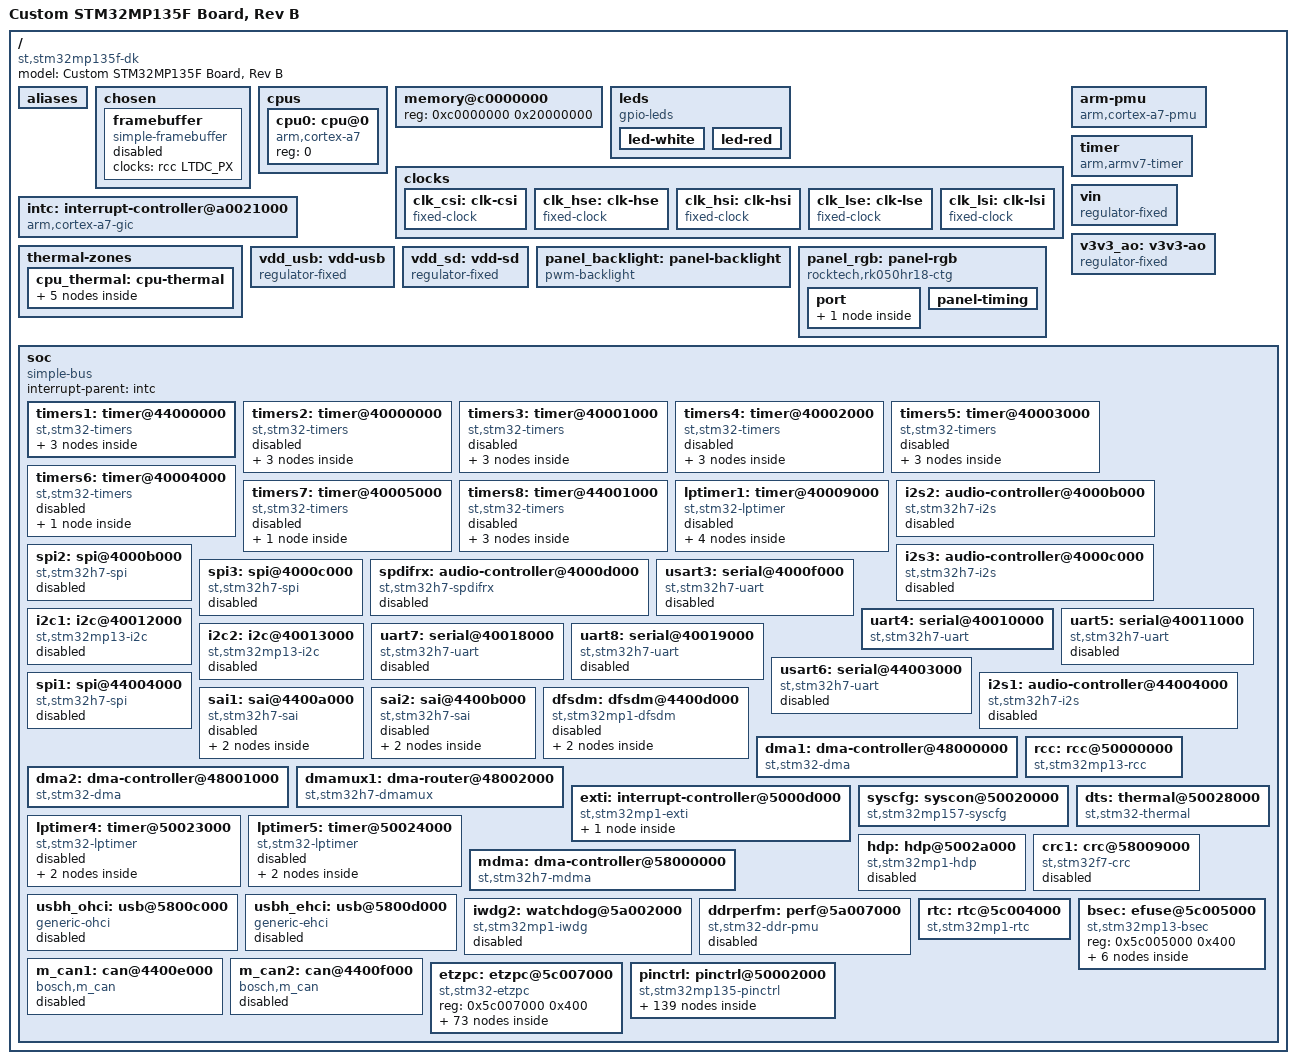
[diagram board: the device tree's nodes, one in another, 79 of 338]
// SPDX-License-Identifier: (GPL-2.0+ OR BSD-3-Clause)
/*
 * Copyright (C) STMicroelectronics 2021 - All Rights Reserved
 * Author: Alexandre Torgue <alexandre.torgue@foss.st.com> for STMicroelectronics.
 */

/dts-v1/;

#include <dt-bindings/gpio/gpio.h>
#include <dt-bindings/input/input.h>
#include <dt-bindings/leds/common.h>
#include <dt-bindings/rtc/rtc-stm32.h>
#include <dt-bindings/interrupt-controller/arm-gic.h>
#include <dt-bindings/clock/stm32mp13-clks.h>
#include <dt-bindings/regulator/st,stm32mp13-regulator.h>
#include <dt-bindings/reset/stm32mp13-resets.h>
#include <dt-bindings/thermal/thermal.h>
#include <dt-bindings/pinctrl/stm32-pinfunc.h>

#define STM32MP1_ETZPC_LPTIM2_ID	1
#define STM32MP1_ETZPC_LPTIM3_ID	2
#define STM32MP1_ETZPC_LTDC_ID		3
#define STM32MP1_ETZPC_DCMIPP_ID	4
#define STM32MP1_ETZPC_USBPHYCTRL_ID	5
#define STM32MP1_ETZPC_USART1_ID	16
#define STM32MP1_ETZPC_USART2_ID	17
#define STM32MP1_ETZPC_SPI4_ID		18
#define STM32MP1_ETZPC_SPI5_ID		19
#define STM32MP1_ETZPC_I2C3_ID		20
#define STM32MP1_ETZPC_I2C4_ID		21
#define STM32MP1_ETZPC_I2C5_ID		22
#define STM32MP1_ETZPC_TIM12_ID		23
#define STM32MP1_ETZPC_TIM13_ID		24
#define STM32MP1_ETZPC_TIM14_ID		25
#define STM32MP1_ETZPC_TIM15_ID		26
#define STM32MP1_ETZPC_TIM16_ID		27
#define STM32MP1_ETZPC_TIM17_ID		28
#define STM32MP1_ETZPC_ADC1_ID		32
#define STM32MP1_ETZPC_ADC2_ID		33
#define STM32MP1_ETZPC_OTG_ID		34
#define STM32MP1_ETZPC_RNG_ID		40
#define STM32MP1_ETZPC_HASH_ID		41
#define STM32MP1_ETZPC_ETH1_ID		48
#define STM32MP1_ETZPC_ETH2_ID		49
#define STM32MP1_ETZPC_SDMMC1_ID	50
#define STM32MP1_ETZPC_SDMMC2_ID	51
#define STM32MP1_ETZPC_FMC_ID		54
#define STM32MP1_ETZPC_QSPI_ID		55

/ {
	#address-cells = <1>;
	#size-cells = <1>;
	model = "Custom STM32MP135F Board, Rev B";
	compatible = "st,stm32mp135f-dk", "st,stm32mp135";

	aliases {
		ethernet0 = &eth1;
		ethernet1 = &eth2;
		mmc0 = &sdmmc1;
		mmc1 = &sdmmc2;
		serial0 = &uart4;
		serial1 = &usart1;
		serial2 = &uart8;
		serial3 = &usart2;
	};

	chosen {
		//bootargs = "ubi.mtd=rootfs root=ubi0:rootfs rootfstype=ubifs";
		bootargs = "root=/dev/mmcblk0p3 rootwait console=tty0 console=ttySTM0,115200";
		stdout-path = "serial0:115200n8";
		#address-cells = <1>;
		#size-cells = <1>;
		ranges;

		framebuffer {
			compatible = "simple-framebuffer";
			clocks = <&rcc LTDC_PX>;
			status = "disabled";
		};
	};

	cpus {
		#address-cells = <1>;
		#size-cells = <0>;

		cpu0: cpu@0 {
			compatible = "arm,cortex-a7";
			device_type = "cpu";
			reg = <0>;
			#cooling-cells = <2>;
		};
	};

	memory@c0000000 {
		device_type = "memory";
		reg = <0xc0000000 0x20000000>;
	};

	leds {
		compatible = "gpio-leds";

		led-white {
			function = LED_FUNCTION_HEARTBEAT;
			color = <LED_COLOR_ID_WHITE>;
			gpios = <&gpioa 4 GPIO_ACTIVE_HIGH>;
			linux,default-trigger = "heartbeat";
			default-state = "off";
		};

		led-red {
			function = LED_FUNCTION_ACTIVITY;
			color = <LED_COLOR_ID_RED>;
			gpios = <&gpioa 13 GPIO_ACTIVE_LOW>;
			linux,default-trigger = "timer";
			default-state = "off";
		};
	};

	clocks {
		clk_csi: clk-csi {
			#clock-cells = <0>;
			compatible = "fixed-clock";
			clock-frequency = <4000000>;
			clock-output-names = "ck_csi";
		};

		clk_hse: clk-hse {
			#clock-cells = <0>;
			compatible = "fixed-clock";
			clock-frequency = <24000000>;
			clock-output-names = "ck_hse";
		};

		clk_hsi: clk-hsi {
			#clock-cells = <0>;
			compatible = "fixed-clock";
			clock-frequency = <64000000>;
			clock-output-names = "ck_hsi";
		};

		clk_lse: clk-lse {
			#clock-cells = <0>;
			compatible = "fixed-clock";
			clock-frequency = <32768>;
			clock-output-names = "ck_lse";
		};

		clk_lsi: clk-lsi {
			#clock-cells = <0>;
			compatible = "fixed-clock";
			clock-frequency = <32000>;
			clock-output-names = "ck_lsi";
		};
	};

	intc: interrupt-controller@a0021000 {
		compatible = "arm,cortex-a7-gic";
		#interrupt-cells = <3>;
		interrupt-controller;
		reg = <0xa0021000 0x1000>,
		      <0xa0022000 0x2000>;
	};

	arm-pmu {
		compatible = "arm,cortex-a7-pmu";
		interrupts = <GIC_SPI 133 IRQ_TYPE_LEVEL_HIGH>;
		interrupt-affinity = <&cpu0>;
		interrupt-parent = <&intc>;
	};

	timer {
		compatible = "arm,armv7-timer";
		interrupts = <GIC_PPI 13 (GIC_CPU_MASK_SIMPLE(1) | IRQ_TYPE_LEVEL_LOW)>,
			     <GIC_PPI 14 (GIC_CPU_MASK_SIMPLE(1) | IRQ_TYPE_LEVEL_LOW)>,
			     <GIC_PPI 11 (GIC_CPU_MASK_SIMPLE(1) | IRQ_TYPE_LEVEL_LOW)>,
			     <GIC_PPI 10 (GIC_CPU_MASK_SIMPLE(1) | IRQ_TYPE_LEVEL_LOW)>;
		interrupt-parent = <&intc>;
		always-on;
	};

	thermal-zones {
		cpu_thermal: cpu-thermal {
			polling-delay-passive = <0>;
			polling-delay = <0>;
			thermal-sensors = <&dts>;

			trips {
				cpu_alert: cpu-alert0 {
					temperature = <95000>;
					hysteresis = <10000>;
					type = "passive";
				};
				cpu_crit: cpu-crit0 {
					temperature = <120000>;
					hysteresis = <0>;
					type = "critical";
				};
			};

			cooling-maps {
				map0 {
					trip = <&cpu_alert>;
					cooling-device = <&cpu0 1 1>;
				};
			};
		};
	};

	vin: vin {
		compatible = "regulator-fixed";
		regulator-name = "vin";
		regulator-min-microvolt = <5000000>;
		regulator-max-microvolt = <5000000>;
		regulator-always-on;
	};

	v3v3_ao: v3v3-ao {
		compatible = "regulator-fixed";
		regulator-name = "v3v3_ao";
		regulator-min-microvolt = <3300000>;
		regulator-max-microvolt = <3300000>;
		regulator-always-on;
	};

	vdd_usb: vdd-usb {
		compatible = "regulator-fixed";
		regulator-name = "vdd_usb";
		regulator-min-microvolt = <3300000>;
		regulator-max-microvolt = <3300000>;
		regulator-always-on;
	};

	vdd_sd: vdd-sd {
		compatible = "regulator-fixed";
		regulator-name = "vdd_sd";
		regulator-min-microvolt = <3300000>;
		regulator-max-microvolt = <3300000>;
		regulator-always-on;
	};

	panel_backlight: panel-backlight {
		compatible = "pwm-backlight";
		pwms = <&pwm1 2 1000000 0>;
		brightness-levels = <0 16 32 64 128 255>;
		default-brightness-level = <4>;
		power-supply = <&v3v3_ao>;
		default-on;
		status = "okay";
	};

	panel_rgb: panel-rgb {
		compatible = "rocktech,rk050hr18-ctg", "panel-dpi";
		enable-gpios = <&gpiog 7 GPIO_ACTIVE_HIGH>;
		backlight = <&panel_backlight>;
		power-supply = <&v3v3_ao>;
		data-mapping = "rgb565";
		status = "okay";

		width-mm = <108>;
		height-mm = <65>;

		port {
			panel_in_rgb: endpoint {
				remote-endpoint = <&ltdc_out_rgb>;
			};
		};

		panel-timing {
			clock-frequency = <24000000>;
			hactive = <800>;
			vactive = <480>;
			hsync-len = <4>;
			hfront-porch = <8>;
			hback-porch = <8>;
			vsync-len = <4>;
			vfront-porch = <16>;
			vback-porch = <16>;
			hsync-active = <0>;
			vsync-active = <0>;
			de-active = <1>;
			pixelclk-active = <1>;
		};
	};

	soc {
		compatible = "simple-bus";
		#address-cells = <1>;
		#size-cells = <1>;
		interrupt-parent = <&intc>;
		ranges;

		timers1: timer@44000000 {
			#address-cells = <1>;
			#size-cells = <0>;
			compatible = "st,stm32-timers";
			reg = <0x44000000 0x400>;
			interrupts = <GIC_SPI 25 IRQ_TYPE_LEVEL_HIGH>,
				     <GIC_SPI 26 IRQ_TYPE_LEVEL_HIGH>,
				     <GIC_SPI 27 IRQ_TYPE_LEVEL_HIGH>,
				     <GIC_SPI 28 IRQ_TYPE_LEVEL_HIGH>;
			interrupt-names = "brk", "up", "trg-com", "cc";
			clocks = <&rcc TIM1_K>;
			clock-names = "int";
			//dmas = <&dmamux1 11 0x400 0x1>,
			//       <&dmamux1 12 0x400 0x1>,
			//       <&dmamux1 13 0x400 0x1>,
			//       <&dmamux1 14 0x400 0x1>,
			//       <&dmamux1 15 0x400 0x1>,
			//       <&dmamux1 16 0x400 0x1>,
			//       <&dmamux1 17 0x400 0x1>;
			//dma-names = "ch1", "ch2", "ch3", "ch4",
			//	    "up", "trig", "com";
			status = "okay";

			pwm1: pwm {
				compatible = "st,stm32-pwm";
				#pwm-cells = <3>;
				status = "okay";
				pinctrl-0 = <&pwm1_pins>;
				pinctrl-names = "default";
			};

			timer@0 {
				compatible = "st,stm32h7-timer-trigger";
				reg = <0>;
				status = "disabled";
			};

			counter {
				compatible = "st,stm32-timer-counter";
				status = "disabled";
			};
		};

		timers2: timer@40000000 {
			#address-cells = <1>;
			#size-cells = <0>;
			compatible = "st,stm32-timers";
			reg = <0x40000000 0x400>;
			interrupts = <GIC_SPI 29 IRQ_TYPE_LEVEL_HIGH>;
			interrupt-names = "global";
			clocks = <&rcc TIM2_K>;
			clock-names = "int";
			dmas = <&dmamux1 18 0x400 0x1>,
			       <&dmamux1 19 0x400 0x1>,
			       <&dmamux1 20 0x400 0x1>,
			       <&dmamux1 21 0x400 0x1>,
			       <&dmamux1 22 0x400 0x1>;
			dma-names = "ch1", "ch2", "ch3", "ch4", "up";
			status = "disabled";

			pwm {
				compatible = "st,stm32-pwm";
				#pwm-cells = <3>;
				status = "disabled";
			};

			timer@1 {
				compatible = "st,stm32h7-timer-trigger";
				reg = <1>;
				status = "disabled";
			};

			counter {
				compatible = "st,stm32-timer-counter";
				status = "disabled";
			};
		};

		timers3: timer@40001000 {
			#address-cells = <1>;
			#size-cells = <0>;
			compatible = "st,stm32-timers";
			reg = <0x40001000 0x400>;
			interrupts = <GIC_SPI 30 IRQ_TYPE_LEVEL_HIGH>;
			interrupt-names = "global";
			clocks = <&rcc TIM3_K>;
			clock-names = "int";
			dmas = <&dmamux1 23 0x400 0x1>,
			       <&dmamux1 24 0x400 0x1>,
			       <&dmamux1 25 0x400 0x1>,
			       <&dmamux1 26 0x400 0x1>,
			       <&dmamux1 27 0x400 0x1>,
			       <&dmamux1 28 0x400 0x1>;
			dma-names = "ch1", "ch2", "ch3", "ch4", "up", "trig";
			status = "disabled";

			pwm {
				compatible = "st,stm32-pwm";
				#pwm-cells = <3>;
				status = "disabled";
			};

			timer@2 {
				compatible = "st,stm32h7-timer-trigger";
				reg = <2>;
				status = "disabled";
			};

			counter {
				compatible = "st,stm32-timer-counter";
				status = "disabled";
			};
		};

		timers4: timer@40002000 {
			#address-cells = <1>;
			#size-cells = <0>;
			compatible = "st,stm32-timers";
			reg = <0x40002000 0x400>;
			interrupts = <GIC_SPI 31 IRQ_TYPE_LEVEL_HIGH>;
			interrupt-names = "global";
			clocks = <&rcc TIM4_K>;
			clock-names = "int";
			dmas = <&dmamux1 29 0x400 0x1>,
			       <&dmamux1 30 0x400 0x1>,
			       <&dmamux1 31 0x400 0x1>,
			       <&dmamux1 32 0x400 0x1>;
			dma-names = "ch1", "ch2", "ch3", "up";
			status = "disabled";

			pwm {
				compatible = "st,stm32-pwm";
				#pwm-cells = <3>;
				status = "disabled";
			};

			timer@3 {
				compatible = "st,stm32h7-timer-trigger";
				reg = <3>;
				status = "disabled";
			};

			counter {
				compatible = "st,stm32-timer-counter";
				status = "disabled";
			};
		};

		timers5: timer@40003000 {
			#address-cells = <1>;
			#size-cells = <0>;
			compatible = "st,stm32-timers";
			reg = <0x40003000 0x400>;
			interrupts = <GIC_SPI 51 IRQ_TYPE_LEVEL_HIGH>;
			interrupt-names = "global";
			clocks = <&rcc TIM5_K>;
			clock-names = "int";
			dmas = <&dmamux1 55 0x400 0x1>,
			       <&dmamux1 56 0x400 0x1>,
			       <&dmamux1 57 0x400 0x1>,
			       <&dmamux1 58 0x400 0x1>,
			       <&dmamux1 59 0x400 0x1>,
			       <&dmamux1 60 0x400 0x1>;
			dma-names = "ch1", "ch2", "ch3", "ch4", "up", "trig";
			status = "disabled";

			pwm {
				compatible = "st,stm32-pwm";
				#pwm-cells = <3>;
				status = "disabled";
			};

			timer@4 {
				compatible = "st,stm32h7-timer-trigger";
				reg = <4>;
				status = "disabled";
			};

			counter {
				compatible = "st,stm32-timer-counter";
				status = "disabled";
			};
		};

		timers6: timer@40004000 {
			#address-cells = <1>;
			#size-cells = <0>;
			compatible = "st,stm32-timers";
			reg = <0x40004000 0x400>;
			interrupts = <GIC_SPI 55 IRQ_TYPE_LEVEL_HIGH>;
			interrupt-names = "global";
			clocks = <&rcc TIM6_K>;
			clock-names = "int";
			dmas = <&dmamux1 69 0x400 0x1>;
			dma-names = "up";
			status = "disabled";

			timer@5 {
				compatible = "st,stm32h7-timer-trigger";
				reg = <5>;
				status = "disabled";
			};
		};

		timers7: timer@40005000 {
			#address-cells = <1>;
			#size-cells = <0>;
			compatible = "st,stm32-timers";
			reg = <0x40005000 0x400>;
			interrupts = <GIC_SPI 56 IRQ_TYPE_LEVEL_HIGH>;
			interrupt-names = "global";
			clocks = <&rcc TIM7_K>;
			clock-names = "int";
			dmas = <&dmamux1 70 0x400 0x1>;
			dma-names = "up";
			status = "disabled";

			timer@6 {
				compatible = "st,stm32h7-timer-trigger";
				reg = <6>;
				status = "disabled";
			};
		};

		timers8: timer@44001000 {
			#address-cells = <1>;
			#size-cells = <0>;
			compatible = "st,stm32-timers";
			reg = <0x44001000 0x400>;
			interrupts = <GIC_SPI 44 IRQ_TYPE_LEVEL_HIGH>,
				     <GIC_SPI 45 IRQ_TYPE_LEVEL_HIGH>,
				     <GIC_SPI 46 IRQ_TYPE_LEVEL_HIGH>,
				     <GIC_SPI 47 IRQ_TYPE_LEVEL_HIGH>;
			interrupt-names = "brk", "up", "trg-com", "cc";
			clocks = <&rcc TIM8_K>;
			clock-names = "int";
			dmas = <&dmamux1 47 0x400 0x1>,
			       <&dmamux1 48 0x400 0x1>,
			       <&dmamux1 49 0x400 0x1>,
			       <&dmamux1 50 0x400 0x1>,
			       <&dmamux1 51 0x400 0x1>,
			       <&dmamux1 52 0x400 0x1>,
			       <&dmamux1 53 0x400 0x1>;
			dma-names = "ch1", "ch2", "ch3", "ch4",
				    "up", "trig", "com";
			status = "disabled";

			pwm {
				compatible = "st,stm32-pwm";
				#pwm-cells = <3>;
				status = "disabled";
			};

			timer@7 {
				compatible = "st,stm32h7-timer-trigger";
				reg = <7>;
				status = "disabled";
			};

			counter {
				compatible = "st,stm32-timer-counter";
				status = "disabled";
			};
		};

		lptimer1: timer@40009000 {
			#address-cells = <1>;
			#size-cells = <0>;
			compatible = "st,stm32-lptimer";
			reg = <0x40009000 0x400>;
			interrupts-extended = <&exti 47 IRQ_TYPE_LEVEL_HIGH>;
			clocks = <&rcc LPTIM1_K>;
			clock-names = "mux";
			//power-domains = <&pd_core_ret>;
			wakeup-source;
			status = "disabled";

			pwm {
				compatible = "st,stm32-pwm-lp";
				#pwm-cells = <3>;
				status = "disabled";
			};

			trigger@0 {
				compatible = "st,stm32-lptimer-trigger";
				reg = <0>;
				status = "disabled";
			};

			counter {
				compatible = "st,stm32-lptimer-counter";
				status = "disabled";
			};

			timer {
				compatible = "st,stm32-lptimer-timer";
				status = "disabled";
			};
		};

		i2s2: audio-controller@4000b000 {
			compatible = "st,stm32h7-i2s";
			#sound-dai-cells = <0>;
			reg = <0x4000b000 0x400>;
			interrupts = <GIC_SPI 37 IRQ_TYPE_LEVEL_HIGH>;
			dmas = <&dmamux1 39 0x400 0x01>,
			       <&dmamux1 40 0x400 0x01>;
			dma-names = "rx", "tx";
			status = "disabled";
		};

		spi2: spi@4000b000 {
			compatible = "st,stm32h7-spi";
			reg = <0x4000b000 0x400>;
			interrupts = <GIC_SPI 37 IRQ_TYPE_LEVEL_HIGH>;
			clocks = <&rcc SPI2_K>;
			resets = <&rcc SPI2_R>;
			#address-cells = <1>;
			#size-cells = <0>;
			dmas = <&dmamux1 39 0x400 0x01>,
			       <&dmamux1 40 0x400 0x01>;
			dma-names = "rx", "tx";
			status = "disabled";
		};

		i2s3: audio-controller@4000c000 {
			compatible = "st,stm32h7-i2s";
			#sound-dai-cells = <0>;
			reg = <0x4000c000 0x400>;
			interrupts = <GIC_SPI 52 IRQ_TYPE_LEVEL_HIGH>;
			dmas = <&dmamux1 61 0x400 0x01>,
			       <&dmamux1 62 0x400 0x01>;
			dma-names = "rx", "tx";
			status = "disabled";
		};

		spi3: spi@4000c000 {
			compatible = "st,stm32h7-spi";
			reg = <0x4000c000 0x400>;
			interrupts = <GIC_SPI 52 IRQ_TYPE_LEVEL_HIGH>;
			clocks = <&rcc SPI3_K>;
			resets = <&rcc SPI3_R>;
			#address-cells = <1>;
			#size-cells = <0>;
			dmas = <&dmamux1 61 0x400 0x01>,
			       <&dmamux1 62 0x400 0x01>;
			dma-names = "rx", "tx";
			status = "disabled";
		};

		spdifrx: audio-controller@4000d000 {
			compatible = "st,stm32h7-spdifrx";
			#sound-dai-cells = <0>;
			reg = <0x4000d000 0x400>;
			clocks = <&rcc SPDIF_K>;
			clock-names = "kclk";
			interrupts = <GIC_SPI 95 IRQ_TYPE_LEVEL_HIGH>;
			dmas = <&dmamux1 93 0x400 0x01>,
			       <&dmamux1 94 0x400 0x01>;
			dma-names = "rx", "rx-ctrl";
			status = "disabled";
		};

		usart3: serial@4000f000 {
			compatible = "st,stm32h7-uart";
			reg = <0x4000f000 0x400>;
			interrupts-extended = <&exti 28 IRQ_TYPE_LEVEL_HIGH>;
			clocks = <&rcc USART3_K>;
			resets = <&rcc USART3_R>;
			wakeup-source;
			//power-domains = <&pd_core_ret>;
			dmas = <&dmamux1 45 0x400 0x5>,
			       <&dmamux1 46 0x400 0x1>;
			dma-names = "rx", "tx";
			status = "disabled";
		};

		uart4: serial@40010000 {
			compatible = "st,stm32h7-uart";
			reg = <0x40010000 0x400>;
			interrupts = <GIC_SPI 53 IRQ_TYPE_LEVEL_HIGH>;
			clocks = <&rcc UART4_K>;
			resets = <&rcc UART4_R>;
			wakeup-source;
			//power-domains = <&pd_core_ret>;
			pinctrl-names = "default", "sleep", "idle";
			pinctrl-0 = <&uart4_pins_a>;
			pinctrl-1 = <&uart4_sleep_pins_a>;
			pinctrl-2 = <&uart4_idle_pins_a>;
			status = "okay";
		};

		uart5: serial@40011000 {
			compatible = "st,stm32h7-uart";
			reg = <0x40011000 0x400>;
			interrupts-extended = <&exti 31 IRQ_TYPE_LEVEL_HIGH>;
			clocks = <&rcc UART5_K>;
			resets = <&rcc UART5_R>;
			wakeup-source;
			//power-domains = <&pd_core_ret>;
			dmas = <&dmamux1 65 0x400 0x5>,
			       <&dmamux1 66 0x400 0x1>;
			dma-names = "rx", "tx";
			status = "disabled";
		};

		i2c1: i2c@40012000 {
			compatible = "st,stm32mp13-i2c";
			reg = <0x40012000 0x400>;
			interrupt-names = "event", "error";
			interrupts = <GIC_SPI 32 IRQ_TYPE_LEVEL_HIGH>,
				     <GIC_SPI 33 IRQ_TYPE_LEVEL_HIGH>;
			clocks = <&rcc I2C1_K>;
			resets = <&rcc I2C1_R>;
			#address-cells = <1>;
			#size-cells = <0>;
			dmas = <&dmamux1 33 0x400 0x1>,
			       <&dmamux1 34 0x400 0x1>;
			dma-names = "rx", "tx";
			st,syscfg-fmp = <&syscfg 0x4 0x1>;
			i2c-analog-filter;
			status = "disabled";
		};

		i2c2: i2c@40013000 {
			compatible = "st,stm32mp13-i2c";
			reg = <0x40013000 0x400>;
			interrupt-names = "event", "error";
			interrupts = <GIC_SPI 34 IRQ_TYPE_LEVEL_HIGH>,
				     <GIC_SPI 35 IRQ_TYPE_LEVEL_HIGH>;
			clocks = <&rcc I2C2_K>;
			resets = <&rcc I2C2_R>;
			#address-cells = <1>;
			#size-cells = <0>;
			dmas = <&dmamux1 35 0x400 0x1>,
			       <&dmamux1 36 0x400 0x1>;
			dma-names = "rx", "tx";
			st,syscfg-fmp = <&syscfg 0x4 0x2>;
			i2c-analog-filter;
			status = "disabled";
		};

		uart7: serial@40018000 {
			compatible = "st,stm32h7-uart";
			reg = <0x40018000 0x400>;
			interrupts-extended = <&exti 32 IRQ_TYPE_LEVEL_HIGH>;
			clocks = <&rcc UART7_K>;
			resets = <&rcc UART7_R>;
			wakeup-source;
			//power-domains = <&pd_core_ret>;
			dmas = <&dmamux1 79 0x400 0x5>,
			       <&dmamux1 80 0x400 0x1>;
			dma-names = "rx", "tx";
			status = "disabled";
		};

		uart8: serial@40019000 {
			compatible = "st,stm32h7-uart";
			reg = <0x40019000 0x400>;
			interrupts-extended = <&exti 33 IRQ_TYPE_LEVEL_HIGH>;
			clocks = <&rcc UART8_K>;
			resets = <&rcc UART8_R>;
			wakeup-source;
			//power-domains = <&pd_core_ret>;
			dmas = <&dmamux1 81 0x400 0x5>,
			       <&dmamux1 82 0x400 0x1>;
			dma-names = "rx", "tx";
			status = "disabled";
		};

		usart6: serial@44003000 {
			compatible = "st,stm32h7-uart";
			reg = <0x44003000 0x400>;
			interrupts-extended = <&exti 29 IRQ_TYPE_LEVEL_HIGH>;
			clocks = <&rcc USART6_K>;
			resets = <&rcc USART6_R>;
			wakeup-source;
			//power-domains = <&pd_core_ret>;
			dmas = <&dmamux1 71 0x400 0x5>,
			       <&dmamux1 72 0x400 0x1>;
			dma-names = "rx", "tx";
			status = "disabled";
		};

		i2s1: audio-controller@44004000 {
			compatible = "st,stm32h7-i2s";
			#sound-dai-cells = <0>;
			reg = <0x44004000 0x400>;
			interrupts = <GIC_SPI 36 IRQ_TYPE_LEVEL_HIGH>;
			dmas = <&dmamux1 37 0x400 0x01>,
			       <&dmamux1 38 0x400 0x01>;
			dma-names = "rx", "tx";
			status = "disabled";
		};

		spi1: spi@44004000 {
			compatible = "st,stm32h7-spi";
			reg = <0x44004000 0x400>;
			interrupts = <GIC_SPI 36 IRQ_TYPE_LEVEL_HIGH>;
			clocks = <&rcc SPI1_K>;
			resets = <&rcc SPI1_R>;
			#address-cells = <1>;
			#size-cells = <0>;
			dmas = <&dmamux1 37 0x400 0x01>,
			       <&dmamux1 38 0x400 0x01>;
			dma-names = "rx", "tx";
			status = "disabled";
		};

		sai1: sai@4400a000 {
			compatible = "st,stm32h7-sai";
			#address-cells = <1>;
			#size-cells = <1>;
			ranges = <0 0x4400a000 0x400>;
			reg = <0x4400a000 0x4>, <0x4400a3f0 0x10>;
			interrupts = <GIC_SPI 87 IRQ_TYPE_LEVEL_HIGH>;
			resets = <&rcc SAI1_R>;
			status = "disabled";

			sai1a: audio-controller@4400a004 {
				#sound-dai-cells = <0>;

				compatible = "st,stm32-sai-sub-a";
				reg = <0x4 0x20>;
				clocks = <&rcc SAI1_K>;
				clock-names = "sai_ck";
				dmas = <&dmamux1 87 0x400 0x01>;
				status = "disabled";
			};

			sai1b: audio-controller@4400a024 {
				#sound-dai-cells = <0>;
				compatible = "st,stm32-sai-sub-b";
				reg = <0x24 0x20>;
				clocks = <&rcc SAI1_K>;
				clock-names = "sai_ck";
				dmas = <&dmamux1 88 0x400 0x01>;
				status = "disabled";
			};
		};

		sai2: sai@4400b000 {
			compatible = "st,stm32h7-sai";
			#address-cells = <1>;
			#size-cells = <1>;
			ranges = <0 0x4400b000 0x400>;
			reg = <0x4400b000 0x4>, <0x4400b3f0 0x10>;
			interrupts = <GIC_SPI 90 IRQ_TYPE_LEVEL_HIGH>;
			resets = <&rcc SAI2_R>;
			status = "disabled";

			sai2a: audio-controller@4400b004 {
				#sound-dai-cells = <0>;
				compatible = "st,stm32-sai-sub-a";
				reg = <0x4 0x20>;
				clocks = <&rcc SAI2_K>;
				clock-names = "sai_ck";
				dmas = <&dmamux1 89 0x400 0x01>;
				status = "disabled";
			};

			sai2b: audio-controller@4400b024 {
				#sound-dai-cells = <0>;
				compatible = "st,stm32-sai-sub-b";
				reg = <0x24 0x20>;
				clocks = <&rcc SAI2_K>;
				clock-names = "sai_ck";
				dmas = <&dmamux1 90 0x400 0x01>;
				status = "disabled";
			};
		};

		dfsdm: dfsdm@4400d000 {
			compatible = "st,stm32mp1-dfsdm";
			reg = <0x4400d000 0x800>;
			clocks = <&rcc DFSDM_K>;
			clock-names = "dfsdm";
			#address-cells = <1>;
			#size-cells = <0>;
			status = "disabled";

			dfsdm0: filter@0 {
				compatible = "st,stm32-dfsdm-adc";
				#io-channel-cells = <1>;
				reg = <0>;
				interrupts = <GIC_SPI 140 IRQ_TYPE_LEVEL_HIGH>;
				dmas = <&dmamux1 101 0x400 0x01>;
				dma-names = "rx";
				status = "disabled";
			};

			dfsdm1: filter@1 {
				compatible = "st,stm32-dfsdm-adc";
				#io-channel-cells = <1>;
				reg = <1>;
				interrupts = <GIC_SPI 141 IRQ_TYPE_LEVEL_HIGH>;
				dmas = <&dmamux1 102 0x400 0x01>;
				dma-names = "rx";
				status = "disabled";
			};
		};

		dma1: dma-controller@48000000 {
			compatible = "st,stm32-dma";
			reg = <0x48000000 0x400>;
			interrupts = <GIC_SPI 11 IRQ_TYPE_LEVEL_HIGH>,
				     <GIC_SPI 12 IRQ_TYPE_LEVEL_HIGH>,
				     <GIC_SPI 13 IRQ_TYPE_LEVEL_HIGH>,
				     <GIC_SPI 14 IRQ_TYPE_LEVEL_HIGH>,
				     <GIC_SPI 15 IRQ_TYPE_LEVEL_HIGH>,
				     <GIC_SPI 16 IRQ_TYPE_LEVEL_HIGH>,
				     <GIC_SPI 17 IRQ_TYPE_LEVEL_HIGH>,
				     <GIC_SPI 48 IRQ_TYPE_LEVEL_HIGH>;
			clocks = <&rcc DMA1>;
			resets = <&rcc DMA1_R>;
			#dma-cells = <4>;
			st,mem2mem;
			dma-requests = <8>;
		};

		dma2: dma-controller@48001000 {
			compatible = "st,stm32-dma";
			reg = <0x48001000 0x400>;
			interrupts = <GIC_SPI 57 IRQ_TYPE_LEVEL_HIGH>,
				     <GIC_SPI 58 IRQ_TYPE_LEVEL_HIGH>,
				     <GIC_SPI 59 IRQ_TYPE_LEVEL_HIGH>,
				     <GIC_SPI 60 IRQ_TYPE_LEVEL_HIGH>,
				     <GIC_SPI 61 IRQ_TYPE_LEVEL_HIGH>,
				     <GIC_SPI 69 IRQ_TYPE_LEVEL_HIGH>,
				     <GIC_SPI 70 IRQ_TYPE_LEVEL_HIGH>,
				     <GIC_SPI 71 IRQ_TYPE_LEVEL_HIGH>;
			clocks = <&rcc DMA2>;
			resets = <&rcc DMA2_R>;
			#dma-cells = <4>;
			st,mem2mem;
			dma-requests = <8>;
		};

		dmamux1: dma-router@48002000 {
			compatible = "st,stm32h7-dmamux";
			reg = <0x48002000 0x40>;
			clocks = <&rcc DMAMUX1>;
			resets = <&rcc DMAMUX1_R>;
			#dma-cells = <3>;
			dma-masters = <&dma1 &dma2>;
			dma-requests = <128>;
			dma-channels = <16>;
		};

		rcc: rcc@50000000 {
			compatible = "st,stm32mp13-rcc", "syscon";
			reg = <0x50000000 0x1000>;
			#clock-cells = <1>;
			#reset-cells = <1>;
			clock-names = "hse", "hsi", "csi", "ck_lse", "lsi";
			clocks = <&clk_hse>,
				 <&clk_hsi>,
				 <&clk_csi>,
				 <&clk_lse>,
				 <&clk_lsi>;
		};

		exti: interrupt-controller@5000d000 {
			compatible = "st,stm32mp1-exti", "syscon";
			interrupt-controller;
			#interrupt-cells = <2>;
			#address-cells = <0>;
			reg = <0x5000d000 0x400>;

			exti-interrupt-map {
				#address-cells = <0>;
				#interrupt-cells = <2>;
				interrupt-map-mask = <0xffffffff 0>;
				interrupt-map =
					<0  0 &intc GIC_SPI 6   IRQ_TYPE_LEVEL_HIGH>,
					<1  0 &intc GIC_SPI 7   IRQ_TYPE_LEVEL_HIGH>,
					<2  0 &intc GIC_SPI 8   IRQ_TYPE_LEVEL_HIGH>,
					<3  0 &intc GIC_SPI 9   IRQ_TYPE_LEVEL_HIGH>,
					<4  0 &intc GIC_SPI 10  IRQ_TYPE_LEVEL_HIGH>,
					<5  0 &intc GIC_SPI 24  IRQ_TYPE_LEVEL_HIGH>,
					<6  0 &intc GIC_SPI 65  IRQ_TYPE_LEVEL_HIGH>,
					<7  0 &intc GIC_SPI 66  IRQ_TYPE_LEVEL_HIGH>,
					<8  0 &intc GIC_SPI 67  IRQ_TYPE_LEVEL_HIGH>,
					<9  0 &intc GIC_SPI 68  IRQ_TYPE_LEVEL_HIGH>,
					<10 0 &intc GIC_SPI 41  IRQ_TYPE_LEVEL_HIGH>,
					<11 0 &intc GIC_SPI 43  IRQ_TYPE_LEVEL_HIGH>,
					<12 0 &intc GIC_SPI 77  IRQ_TYPE_LEVEL_HIGH>,
					<13 0 &intc GIC_SPI 78  IRQ_TYPE_LEVEL_HIGH>,
					<14 0 &intc GIC_SPI 106 IRQ_TYPE_LEVEL_HIGH>,
					<15 0 &intc GIC_SPI 109 IRQ_TYPE_LEVEL_HIGH>,
					<16 0 &intc GIC_SPI 1   IRQ_TYPE_LEVEL_HIGH>,
					<19 0 &intc GIC_SPI 3   IRQ_TYPE_LEVEL_HIGH>,
					<21 0 &intc GIC_SPI 32  IRQ_TYPE_LEVEL_HIGH>,
					<22 0 &intc GIC_SPI 34  IRQ_TYPE_LEVEL_HIGH>,
					<23 0 &intc GIC_SPI 73  IRQ_TYPE_LEVEL_HIGH>,
					<24 0 &intc GIC_SPI 93  IRQ_TYPE_LEVEL_HIGH>,
					<25 0 &intc GIC_SPI 114 IRQ_TYPE_LEVEL_HIGH>,
					<26 0 &intc GIC_SPI 38  IRQ_TYPE_LEVEL_HIGH>,
					<27 0 &intc GIC_SPI 39  IRQ_TYPE_LEVEL_HIGH>,
					<28 0 &intc GIC_SPI 40  IRQ_TYPE_LEVEL_HIGH>,
					<29 0 &intc GIC_SPI 72  IRQ_TYPE_LEVEL_HIGH>,
					<30 0 &intc GIC_SPI 53  IRQ_TYPE_LEVEL_HIGH>,
					<31 0 &intc GIC_SPI 54  IRQ_TYPE_LEVEL_HIGH>,
					<32 0 &intc GIC_SPI 83  IRQ_TYPE_LEVEL_HIGH>,
					<33 0 &intc GIC_SPI 84  IRQ_TYPE_LEVEL_HIGH>,
					<42 0 &intc GIC_SPI 75  IRQ_TYPE_LEVEL_HIGH>,
					<43 0 &intc GIC_SPI 75  IRQ_TYPE_LEVEL_HIGH>,
					<44 0 &intc GIC_SPI 96  IRQ_TYPE_LEVEL_HIGH>,
					<47 0 &intc GIC_SPI 92  IRQ_TYPE_LEVEL_HIGH>,
					<48 0 &intc GIC_SPI 116 IRQ_TYPE_LEVEL_HIGH>,
					<50 0 &intc GIC_SPI 117 IRQ_TYPE_LEVEL_HIGH>,
					<52 0 &intc GIC_SPI 118 IRQ_TYPE_LEVEL_HIGH>,
					<53 0 &intc GIC_SPI 119 IRQ_TYPE_LEVEL_HIGH>,
					<68 0 &intc GIC_SPI 63  IRQ_TYPE_LEVEL_HIGH>,
					<70 0 &intc GIC_SPI 98  IRQ_TYPE_LEVEL_HIGH>;
			};
		};

		syscfg: syscon@50020000 {
			compatible = "st,stm32mp157-syscfg", "syscon";
			reg = <0x50020000 0x400>;
			clocks = <&rcc SYSCFG>;
		};

		lptimer4: timer@50023000 {
			compatible = "st,stm32-lptimer";
			reg = <0x50023000 0x400>;
			interrupts-extended = <&exti 52 IRQ_TYPE_LEVEL_HIGH>;
			clocks = <&rcc LPTIM4_K>;
			clock-names = "mux";
			//power-domains = <&pd_core_ret>;
			wakeup-source;
			status = "disabled";

			pwm {
				compatible = "st,stm32-pwm-lp";
				#pwm-cells = <3>;
				status = "disabled";
			};

			timer {
				compatible = "st,stm32-lptimer-timer";
				status = "disabled";
			};
		};

		lptimer5: timer@50024000 {
			compatible = "st,stm32-lptimer";
			reg = <0x50024000 0x400>;
			interrupts-extended = <&exti 53 IRQ_TYPE_LEVEL_HIGH>;
			clocks = <&rcc LPTIM5_K>;
			clock-names = "mux";
			//power-domains = <&pd_core_ret>;
			wakeup-source;
			status = "disabled";

			pwm {
				compatible = "st,stm32-pwm-lp";
				#pwm-cells = <3>;
				status = "disabled";
			};

			timer {
				compatible = "st,stm32-lptimer-timer";
				status = "disabled";
			};
		};

		dts: thermal@50028000 {
			compatible = "st,stm32-thermal";
			interrupts = <GIC_SPI 124 IRQ_TYPE_LEVEL_HIGH>;
			clocks = <&rcc DTS>;
			clock-names = "pclk";
			#thermal-sensor-cells = <0>;
			reg = <0x50028000 0x100>;
			status = "okay";
		};

		hdp: hdp@5002a000 {
			compatible = "st,stm32mp1-hdp";
			reg = <0x5002a000 0x400>;
			clocks = <&rcc HDP>;
			clock-names = "hdp";
			status = "disabled";
		};

		mdma: dma-controller@58000000 {
			compatible = "st,stm32h7-mdma";
			reg = <0x58000000 0x1000>;
			interrupts = <GIC_SPI 107 IRQ_TYPE_LEVEL_HIGH>;
			clocks = <&rcc MDMA>;
			#dma-cells = <5>;
			dma-channels = <32>;
			dma-requests = <48>;
		};

		crc1: crc@58009000 {
			compatible = "st,stm32f7-crc";
			reg = <0x58009000 0x400>;
			clocks = <&rcc CRC1>;
			status = "disabled";
		};

		usbh_ohci: usb@5800c000 {
			compatible = "generic-ohci";
			reg = <0x5800c000 0x1000>;
			clocks = <&usbphyc>, <&rcc USBH>;
			resets = <&rcc USBH_R>;
			interrupts = <GIC_SPI 75 IRQ_TYPE_LEVEL_HIGH>;
			//power-domains = <&pd_core>;
			wakeup-source;
			status = "disabled";
		};

		usbh_ehci: usb@5800d000 {
			compatible = "generic-ehci";
			reg = <0x5800d000 0x1000>;
			clocks = <&usbphyc>, <&rcc USBH>;
			resets = <&rcc USBH_R>;
			interrupts = <GIC_SPI 76 IRQ_TYPE_LEVEL_HIGH>;
			companion = <&usbh_ohci>;
			//power-domains = <&pd_core>;
			wakeup-source;
			status = "disabled";
		};

		iwdg2: watchdog@5a002000 {
			compatible = "st,stm32mp1-iwdg";
			reg = <0x5a002000 0x400>;
			clocks = <&rcc IWDG2>, <&clk_lsi>;
			clock-names = "pclk", "lsi";
			status = "disabled";
		};

		ddrperfm: perf@5a007000 {
			compatible = "st,stm32-ddr-pmu";
			reg = <0x5a007000 0x400>;
			clocks = <&rcc DDRPERFM>;
			resets = <&rcc DDRPERFM_R>;
			status = "disabled";
		};

		rtc: rtc@5c004000 {
			compatible = "st,stm32mp1-rtc";
			reg = <0x5c004000 0x400>;
			interrupts-extended = <&exti 19 IRQ_TYPE_LEVEL_HIGH>;
			clocks = <&rcc RTCAPB>,
				 <&rcc RTC>;
			clock-names = "pclk", "rtc_ck";
			pinctrl-names = "default";
			status = "okay";
		};

		bsec: efuse@5c005000 {
			compatible = "st,stm32mp13-bsec";
			reg = <0x5c005000 0x400>;
			#address-cells = <1>;
			#size-cells = <1>;

			part_number_otp: part-number-otp@4 {
				reg = <0x4 0x2>;
				bits = <0 12>;
			};
			vrefint: vrefin-cal@52 {
				reg = <0x52 0x2>;
			};
			ts_cal1: calib@5c {
				reg = <0x5c 0x2>;
			};
			ts_cal2: calib@5e {
				reg = <0x5e 0x2>;
			};
			ethernet_mac1_address: mac1@e4 {
				reg = <0xe4 0x6>;
			};
			ethernet_mac2_address: mac2@ea {
				reg = <0xea 0x6>;
			};
		};

		m_can1: can@4400e000 {
			compatible = "bosch,m_can";
			reg = <0x4400e000 0x400>, <0x44011000 0x1400>;
			reg-names = "m_can", "message_ram";
			interrupts = <GIC_SPI 20 IRQ_TYPE_LEVEL_HIGH>,
				     <GIC_SPI 22 IRQ_TYPE_LEVEL_HIGH>;
			interrupt-names = "int0", "int1";
			clocks = <&clk_hse>, <&rcc FDCAN_K>;
			clock-names = "hclk", "cclk";
			bosch,mram-cfg = <0x0 0 0 32 0 0 2 2>;
			status = "disabled";
		};

		m_can2: can@4400f000 {
			compatible = "bosch,m_can";
			reg = <0x4400f000 0x400>, <0x44011000 0x2800>;
			reg-names = "m_can", "message_ram";
			interrupts = <GIC_SPI 21 IRQ_TYPE_LEVEL_HIGH>,
				     <GIC_SPI 23 IRQ_TYPE_LEVEL_HIGH>;
			interrupt-names = "int0", "int1";
			clocks = <&clk_hse>, <&rcc FDCAN_K>;
			clock-names = "hclk", "cclk";
			bosch,mram-cfg = <0x1400 0 0 32 0 0 2 2>;
			status = "disabled";
		};

		etzpc: etzpc@5c007000 {
			compatible = "st,stm32-etzpc", "simple-bus";
			reg = <0x5c007000 0x400>;
			#address-cells = <1>;
			#size-cells = <1>;
			#access-controller-cells = <1>;
			ranges;

			adc_1: adc@48003000 {
				compatible = "st,stm32mp13-adc-core";
				reg = <0x48003000 0x400>;
				interrupts = <GIC_SPI 18 IRQ_TYPE_LEVEL_HIGH>;
				clocks = <&rcc ADC1>, <&rcc ADC1_K>;
				clock-names = "bus", "adc";
				interrupt-controller;
				#interrupt-cells = <1>;
				#address-cells = <1>;
				#size-cells = <0>;
				access-controllers = <&etzpc STM32MP1_ETZPC_ADC1_ID>;
				status = "disabled";

				adc1: adc@0 {
					compatible = "st,stm32mp13-adc";
					#io-channel-cells = <1>;
					#address-cells = <1>;
					#size-cells = <0>;
					reg = <0x0>;
					interrupt-parent = <&adc_1>;
					interrupts = <0>;
					dmas = <&dmamux1 9 0x400 0x80000001>;
					dma-names = "rx";
					nvmem-cells = <&vrefint>;
					nvmem-cell-names = "vrefint";
					status = "disabled";

					channel@18 {
						reg = <18>;
						label = "vrefint";
					};
				};
			};

			adc_2: adc@48004000 {
				reg = <0x48004000 0x400>;
				compatible = "st,stm32mp13-adc-core";
				interrupts = <GIC_SPI 19 IRQ_TYPE_LEVEL_HIGH>;
				clocks = <&rcc ADC2>, <&rcc ADC2_K>;
				clock-names = "bus", "adc";
				interrupt-controller;
				#interrupt-cells = <1>;
				#address-cells = <1>;
				#size-cells = <0>;
				access-controllers = <&etzpc STM32MP1_ETZPC_ADC2_ID>;
				status = "disabled";

				adc2: adc@0 {
					compatible = "st,stm32mp13-adc";
					#io-channel-cells = <1>;
					#address-cells = <1>;
					#size-cells = <0>;
					reg = <0x0>;
					interrupt-parent = <&adc_2>;
					interrupts = <0>;
					dmas = <&dmamux1 10 0x400 0x80000001>;
					dma-names = "rx";
					status = "disabled";

					channel@13 {
						reg = <13>;
						label = "vrefint";
					};
					channel@14 {
						reg = <14>;
						label = "vddcore";
					};
					channel@16 {
						reg = <16>;
						label = "vddcpu";
					};
					channel@17 {
						reg = <17>;
						label = "vddq_ddr";
					};
				};
			};

			dcmipp: dcmipp@5a000000 {
				compatible = "st,stm32mp13-dcmipp";
				reg = <0x5a000000 0x400>;
				interrupts = <GIC_SPI 79 IRQ_TYPE_LEVEL_HIGH>;
				resets = <&rcc DCMIPP_R>;
				clocks = <&rcc DCMIPP_K>;
				clock-names = "kclk";
				access-controllers = <&etzpc STM32MP1_ETZPC_DCMIPP_ID>;
				status = "disabled";
			};

			ltdc: display-controller@5a001000 {
				compatible = "st,stm32-ltdc";
				reg = <0x5a001000 0x400>;
				interrupts = <GIC_SPI 88 IRQ_TYPE_LEVEL_HIGH>,
					     <GIC_SPI 89 IRQ_TYPE_LEVEL_HIGH>;
				clocks = <&rcc LTDC_PX>;
				clock-names = "lcd";
				access-controllers = <&etzpc STM32MP1_ETZPC_LTDC_ID>;
				pinctrl-names = "default", "sleep";
				pinctrl-0 = <&ltdc_pins_a>;
				pinctrl-1 = <&ltdc_sleep_pins_a>;
				status = "okay";

				port {
					ltdc_out_rgb: endpoint {
						remote-endpoint = <&panel_in_rgb>;
					};
				};
			};

			usbotg_hs: usb@49000000 {
				compatible = "st,stm32mp15-hsotg", "snps,dwc2";
				reg = <0x49000000 0x40000>;
				clocks = <&rcc USBO_K>;
				clock-names = "otg";
				resets = <&rcc USBO_R>;
				reset-names = "dwc2";
				interrupts = <GIC_SPI 96 IRQ_TYPE_LEVEL_HIGH>;
				g-rx-fifo-size = <512>;
				g-np-tx-fifo-size = <32>;
				g-tx-fifo-size = <256 16 16 16 16 16 16 16>;
				dr_mode = "peripheral";
				usb-role-switch;
				role-switch-default-mode = "peripheral";
				otg-rev = <0x200>;
				//usb33d-supply = <&scmi_usb33>;
				//power-domains = <&pd_core>;
				wakeup-source;
				access-controllers = <&etzpc STM32MP1_ETZPC_OTG_ID>;
				phys = <&usbphyc_port1 0>;
				phy-names = "usb2-phy";
				status = "okay";
			};

			usart1: serial@4c000000 {
				compatible = "st,stm32h7-uart";
				reg = <0x4c000000 0x400>;
				interrupts-extended = <&exti 26 IRQ_TYPE_LEVEL_HIGH>;
				clocks = <&rcc USART1_K>;
				resets = <&rcc USART1_R>;
				wakeup-source;
				//power-domains = <&pd_core_ret>;
				dmas = <&dmamux1 41 0x400 0x5>,
				       <&dmamux1 42 0x400 0x1>;
				dma-names = "rx", "tx";
				access-controllers = <&etzpc STM32MP1_ETZPC_USART1_ID>;
				status = "disabled";
			};

			usart2: serial@4c001000 {
				compatible = "st,stm32h7-uart";
				reg = <0x4c001000 0x400>;
				interrupts-extended = <&exti 27 IRQ_TYPE_LEVEL_HIGH>;
				clocks = <&rcc USART2_K>;
				resets = <&rcc USART2_R>;
				wakeup-source;
				//power-domains = <&pd_core_ret>;
				dmas = <&dmamux1 43 0x400 0x5>,
				       <&dmamux1 44 0x400 0x1>;
				dma-names = "rx", "tx";
				access-controllers = <&etzpc STM32MP1_ETZPC_USART2_ID>;
				status = "disabled";
			};

			i2s4: audio-controller@4c002000 {
				compatible = "st,stm32h7-i2s";
				#sound-dai-cells = <0>;
				reg = <0x4c002000 0x400>;
				interrupts = <GIC_SPI 85 IRQ_TYPE_LEVEL_HIGH>;
				dmas = <&dmamux1 83 0x400 0x01>,
				       <&dmamux1 84 0x400 0x01>;
				dma-names = "rx", "tx";
				access-controllers = <&etzpc STM32MP1_ETZPC_SPI4_ID>;
				status = "disabled";
			};

			spi4: spi@4c002000 {
				compatible = "st,stm32h7-spi";
				reg = <0x4c002000 0x400>;
				interrupts = <GIC_SPI 85 IRQ_TYPE_LEVEL_HIGH>;
				clocks = <&rcc SPI4_K>;
				resets = <&rcc SPI4_R>;
				#address-cells = <1>;
				#size-cells = <0>;
				dmas = <&dmamux1 83 0x400 0x01>,
				       <&dmamux1 84 0x400 0x01>;
				dma-names = "rx", "tx";
				access-controllers = <&etzpc STM32MP1_ETZPC_SPI4_ID>;
				status = "disabled";
			};

			spi5: spi@4c003000 {
				compatible = "st,stm32h7-spi";
				reg = <0x4c003000 0x400>;
				interrupts = <GIC_SPI 86 IRQ_TYPE_LEVEL_HIGH>;
				clocks = <&rcc SPI5_K>;
				resets = <&rcc SPI5_R>;
				#address-cells = <1>;
				#size-cells = <0>;
				dmas = <&dmamux1 85 0x400 0x01>,
				       <&dmamux1 86 0x400 0x01>;
				dma-names = "rx", "tx";
				access-controllers = <&etzpc STM32MP1_ETZPC_SPI5_ID>;
				status = "disabled";
			};

			i2c3: i2c@4c004000 {
				compatible = "st,stm32mp13-i2c";
				reg = <0x4c004000 0x400>;
				interrupt-names = "event", "error";
				interrupts = <GIC_SPI 73 IRQ_TYPE_LEVEL_HIGH>,
					     <GIC_SPI 74 IRQ_TYPE_LEVEL_HIGH>;
				clocks = <&rcc I2C3_K>;
				resets = <&rcc I2C3_R>;
				#address-cells = <1>;
				#size-cells = <0>;
				dmas = <&dmamux1 73 0x400 0x1>,
				       <&dmamux1 74 0x400 0x1>;
				dma-names = "rx", "tx";
				st,syscfg-fmp = <&syscfg 0x4 0x4>;
				i2c-analog-filter;
				access-controllers = <&etzpc STM32MP1_ETZPC_I2C3_ID>;
				status = "disabled";
			};

			i2c4: i2c@4c005000 {
				compatible = "st,stm32mp13-i2c";
				reg = <0x4c005000 0x400>;
				interrupt-names = "event", "error";
				interrupts = <GIC_SPI 93 IRQ_TYPE_LEVEL_HIGH>,
					     <GIC_SPI 94 IRQ_TYPE_LEVEL_HIGH>;
				clocks = <&rcc I2C4_K>;
				resets = <&rcc I2C4_R>;
				#address-cells = <1>;
				#size-cells = <0>;
				dmas = <&dmamux1 75 0x400 0x1>,
				       <&dmamux1 76 0x400 0x1>;
				dma-names = "rx", "tx";
				st,syscfg-fmp = <&syscfg 0x4 0x8>;
				i2c-analog-filter;
				access-controllers = <&etzpc STM32MP1_ETZPC_I2C4_ID>;
				status = "disabled";
			};

			i2c5: i2c@4c006000 {
				compatible = "st,stm32mp13-i2c";
				reg = <0x4c006000 0x400>;
				interrupt-names = "event", "error";
				interrupts = <GIC_SPI 114 IRQ_TYPE_LEVEL_HIGH>,
					     <GIC_SPI 115 IRQ_TYPE_LEVEL_HIGH>;
				clocks = <&rcc I2C5_K>;
				resets = <&rcc I2C5_R>;
				#address-cells = <1>;
				#size-cells = <0>;
				st,syscfg-fmp = <&syscfg 0x4 0x10>;
				i2c-analog-filter;
				access-controllers = <&etzpc STM32MP1_ETZPC_I2C5_ID>;
				pinctrl-names = "default", "sleep";
				pinctrl-0 = <&i2c5_pins_a>;
				pinctrl-1 = <&i2c5_sleep_pins_a>;
				i2c-scl-rising-time-ns = <170>;
				i2c-scl-falling-time-ns = <5>;
				clock-frequency = <400000>;
				status = "okay";

				goodix: goodix-ts@5d {
					compatible = "goodix,gt911";
					reg = <0x5d>;
					pinctrl-names = "default";
					pinctrl-0 = <&goodix_pins_a>;
					interrupt-parent = <&gpioh>;
					interrupts = <12 IRQ_TYPE_EDGE_FALLING>;
					reset-gpios = <&gpiob 7 GPIO_ACTIVE_LOW>;
					AVDD28-supply = <&v3v3_ao>;
					VDDIO-supply = <&v3v3_ao>;
					touchscreen-size-x = <800>;
					touchscreen-size-y = <480>;
					status = "okay" ;
				};
			};

			timers12: timer@4c007000 {
				#address-cells = <1>;
				#size-cells = <0>;
				compatible = "st,stm32-timers";
				reg = <0x4c007000 0x400>;
				interrupts = <GIC_SPI 104 IRQ_TYPE_LEVEL_HIGH>;
				interrupt-names = "global";
				clocks = <&rcc TIM12_K>;
				clock-names = "int";
				access-controllers = <&etzpc STM32MP1_ETZPC_TIM12_ID>;
				status = "disabled";

				pwm {
					compatible = "st,stm32-pwm";
					#pwm-cells = <3>;
					status = "disabled";
				};

				timer@11 {
					compatible = "st,stm32h7-timer-trigger";
					reg = <11>;
					status = "disabled";
				};
			};

			timers13: timer@4c008000 {
				#address-cells = <1>;
				#size-cells = <0>;
				compatible = "st,stm32-timers";
				reg = <0x4c008000 0x400>;
				interrupts = <GIC_SPI 111 IRQ_TYPE_LEVEL_HIGH>;
				interrupt-names = "global";
				clocks = <&rcc TIM13_K>;
				clock-names = "int";
				access-controllers = <&etzpc STM32MP1_ETZPC_TIM13_ID>;
				status = "disabled";

				pwm {
					compatible = "st,stm32-pwm";
					#pwm-cells = <3>;
					status = "disabled";
				};

				timer@12 {
					compatible = "st,stm32h7-timer-trigger";
					reg = <12>;
					status = "disabled";
				};
			};

			timers14: timer@4c009000 {
				#address-cells = <1>;
				#size-cells = <0>;
				compatible = "st,stm32-timers";
				reg = <0x4c009000 0x400>;
				interrupts = <GIC_SPI 112 IRQ_TYPE_LEVEL_HIGH>;
				interrupt-names = "global";
				clocks = <&rcc TIM14_K>;
				clock-names = "int";
				access-controllers = <&etzpc STM32MP1_ETZPC_TIM14_ID>;
				status = "disabled";

				pwm {
					compatible = "st,stm32-pwm";
					#pwm-cells = <3>;
					status = "disabled";
				};

				timer@13 {
					compatible = "st,stm32h7-timer-trigger";
					reg = <13>;
					status = "disabled";
				};
			};

			timers15: timer@4c00a000 {
				#address-cells = <1>;
				#size-cells = <0>;
				compatible = "st,stm32-timers";
				reg = <0x4c00a000 0x400>;
				interrupts = <GIC_SPI 101 IRQ_TYPE_LEVEL_HIGH>;
				interrupt-names = "global";
				clocks = <&rcc TIM15_K>;
				clock-names = "int";
				dmas = <&dmamux1 105 0x400 0x1>,
				       <&dmamux1 106 0x400 0x1>,
				       <&dmamux1 107 0x400 0x1>,
				       <&dmamux1 108 0x400 0x1>;
				dma-names = "ch1", "up", "trig", "com";
				access-controllers = <&etzpc STM32MP1_ETZPC_TIM15_ID>;
				status = "disabled";

				pwm {
					compatible = "st,stm32-pwm";
					#pwm-cells = <3>;
					status = "disabled";
				};

				timer@14 {
					compatible = "st,stm32h7-timer-trigger";
					reg = <14>;
					status = "disabled";
				};
			};

			timers16: timer@4c00b000 {
				#address-cells = <1>;
				#size-cells = <0>;
				compatible = "st,stm32-timers";
				reg = <0x4c00b000 0x400>;
				interrupts = <GIC_SPI 102 IRQ_TYPE_LEVEL_HIGH>;
				interrupt-names = "global";
				clocks = <&rcc TIM16_K>;
				clock-names = "int";
				dmas = <&dmamux1 109 0x400 0x1>,
				       <&dmamux1 110 0x400 0x1>;
				dma-names = "ch1", "up";
				access-controllers = <&etzpc STM32MP1_ETZPC_TIM16_ID>;
				status = "disabled";

				pwm {
					compatible = "st,stm32-pwm";
					#pwm-cells = <3>;
					status = "disabled";
				};

				timer@15 {
					compatible = "st,stm32h7-timer-trigger";
					reg = <15>;
					status = "disabled";
				};
			};

			timers17: timer@4c00c000 {
				#address-cells = <1>;
				#size-cells = <0>;
				compatible = "st,stm32-timers";
				reg = <0x4c00c000 0x400>;
				interrupts = <GIC_SPI 103 IRQ_TYPE_LEVEL_HIGH>;
				interrupt-names = "global";
				clocks = <&rcc TIM17_K>;
				clock-names = "int";
				dmas = <&dmamux1 111 0x400 0x1>,
				       <&dmamux1 112 0x400 0x1>;
				dma-names = "ch1", "up";
				access-controllers = <&etzpc STM32MP1_ETZPC_TIM17_ID>;
				status = "disabled";

				pwm {
					compatible = "st,stm32-pwm";
					#pwm-cells = <3>;
					status = "disabled";
				};

				timer@16 {
					compatible = "st,stm32h7-timer-trigger";
					reg = <16>;
					status = "disabled";
				};
			};

			lptimer2: timer@50021000 {
				#address-cells = <1>;
				#size-cells = <0>;
				compatible = "st,stm32-lptimer";
				reg = <0x50021000 0x400>;
				interrupts-extended = <&exti 48 IRQ_TYPE_LEVEL_HIGH>;
				clocks = <&rcc LPTIM2_K>;
				clock-names = "mux";
				//power-domains = <&pd_core_ret>;
				wakeup-source;
				access-controllers = <&etzpc STM32MP1_ETZPC_LPTIM2_ID>;
				status = "disabled";

				pwm {
					compatible = "st,stm32-pwm-lp";
					#pwm-cells = <3>;
					status = "disabled";
				};

				trigger@1 {
					compatible = "st,stm32-lptimer-trigger";
					reg = <1>;
					status = "disabled";
				};

				counter {
					compatible = "st,stm32-lptimer-counter";
					status = "disabled";
				};

				timer {
					compatible = "st,stm32-lptimer-timer";
					status = "disabled";
				};
			};

			lptimer3: timer@50022000 {
				#address-cells = <1>;
				#size-cells = <0>;
				compatible = "st,stm32-lptimer";
				reg = <0x50022000 0x400>;
				interrupts-extended = <&exti 50 IRQ_TYPE_LEVEL_HIGH>;
				clocks = <&rcc LPTIM3_K>;
				clock-names = "mux";
				//power-domains = <&pd_core_ret>;
				wakeup-source;
				access-controllers = <&etzpc STM32MP1_ETZPC_LPTIM3_ID>;
				status = "disabled";

				pwm {
					compatible = "st,stm32-pwm-lp";
					#pwm-cells = <3>;
					status = "disabled";
				};

				trigger@2 {
					compatible = "st,stm32-lptimer-trigger";
					reg = <2>;
					status = "disabled";
				};

				timer {
					compatible = "st,stm32-lptimer-timer";
					status = "disabled";
				};
			};

			hash: hash@54003000 {
				compatible = "st,stm32mp13-hash";
				reg = <0x54003000 0x400>;
				interrupts = <GIC_SPI 81 IRQ_TYPE_LEVEL_HIGH>;
				clocks = <&rcc HASH1>;
				resets = <&rcc HASH1_R>;
				dmas = <&mdma 30 0x2 0x1000a02 0x0 0x0 0x0>;
				dma-names = "in";
				access-controllers = <&etzpc STM32MP1_ETZPC_HASH_ID>;
				status = "disabled";
			};

			rng: rng@54004000 {
				compatible = "st,stm32mp13-rng";
				reg = <0x54004000 0x400>;
				clocks = <&rcc RNG1_K>;
				resets = <&rcc RNG1_R>;
				access-controllers = <&etzpc STM32MP1_ETZPC_RNG_ID>;
				status = "disabled";
			};

			fmc: memory-controller@58002000 {
				compatible = "st,stm32mp1-fmc2-ebi";
				reg = <0x58002000 0x1000>;
				ranges = <0 0 0x60000000 0x04000000>, /* EBI CS 1 */
					 <1 0 0x64000000 0x04000000>, /* EBI CS 2 */
					 <2 0 0x68000000 0x04000000>, /* EBI CS 3 */
					 <3 0 0x6c000000 0x04000000>, /* EBI CS 4 */
					 <4 0 0x80000000 0x10000000>; /* NAND */
				#address-cells = <2>;
				#size-cells = <1>;
				clocks = <&rcc FMC_K>;
				resets = <&rcc FMC_R>;
				access-controllers = <&etzpc STM32MP1_ETZPC_FMC_ID>;
				pinctrl-names = "default";
				pinctrl-0 = <&fmc_nand_pins>;
				status = "okay";

				nand-controller@4,0 {
					compatible = "st,stm32mp1-fmc2-nfc";
					reg = <4 0x00000000 0x1000>,
					      <4 0x08010000 0x1000>,
					      <4 0x08020000 0x1000>,
					      <4 0x01000000 0x1000>,
					      <4 0x09010000 0x1000>,
					      <4 0x09020000 0x1000>;
					#address-cells = <1>;
					#size-cells = <0>;
					interrupts = <GIC_SPI 49 IRQ_TYPE_LEVEL_HIGH>;
					dmas = <&mdma 24 0x2 0x12000a02 0x0 0x0>,
					       <&mdma 24 0x2 0x12000a08 0x0 0x0>,
					       <&mdma 25 0x2 0x12000a0a 0x0 0x0>;
					dma-names = "tx", "rx", "ecc";
					status = "okay";

					nand@0 {
						reg = <0>;
						nand-on-flash-bbt;
						nand-ecc-algo = "bch";
						nand-ecc-strength = <8>;
						nand-ecc-step-size = <512>;
						#address-cells = <1>;
						#size-cells = <1>;

						partitions {
							compatible = "fixed-partitions";
							#address-cells = <1>;
							#size-cells = <1>;

							partition@0 {
							    label = "bootloader";
							    reg = <0x00000000 0x00080000>; /* blocks 0-1 */
							    read-only;
							};
							partition@80000 {
							    label = "ptable";
							    reg = <0x00080000 0x00040000>; /* block 2 */
							    /* Writable so the hardened-PT mission step
							     * can flash_erase + nandwrite the primary
							     * PT block; the bootloader recovers from
							     * the on-flash mirror at block
							     * NAND_BLOCK_PT_MIRROR. */
							};
							partition@c0000 {
							    label = "dtb";
							    reg = <0x000c0000 0x00040000>; /* block 3 */
							};
							partition@100000 {
							    label = "kernel";
							    reg = <0x00100000 0x03200000>; /* blocks 4-203, 50 MB */
							};
							partition@3300000 {
							    label = "rootfs";
							    reg = <0x03300000 0x1cd00000>; /* block 204 to end, ~461 MB */
							};
						};
					};
				};
			};

			qspi: spi@58003000 {
				compatible = "st,stm32f469-qspi";
				reg = <0x58003000 0x1000>, <0x70000000 0x10000000>;
				reg-names = "qspi", "qspi_mm";
				#address-cells = <1>;
				#size-cells = <0>;
				interrupts = <GIC_SPI 91 IRQ_TYPE_LEVEL_HIGH>;
				dmas = <&mdma 26 0x2 0x10100002 0x0 0x0>,
				       <&mdma 26 0x2 0x10100008 0x0 0x0>;
				dma-names = "tx", "rx";
				clocks = <&rcc QSPI_K>;
				resets = <&rcc QSPI_R>;
				access-controllers = <&etzpc STM32MP1_ETZPC_QSPI_ID>;
				status = "disabled";
			};

			sdmmc1: mmc@58005000 {
				compatible = "st,stm32-sdmmc2", "arm,pl18x", "arm,primecell";
				arm,primecell-periphid = <0x20253180>;
				reg = <0x58005000 0x1000>, <0x58006000 0x1000>;
				interrupts = <GIC_SPI 50 IRQ_TYPE_LEVEL_HIGH>;
				clocks = <&rcc SDMMC1_K>;
				clock-names = "apb_pclk";
				assigned-clocks = <&rcc SDMMC1_K>;
				assigned-clock-parents = <&clk_hsi>;
				resets = <&rcc SDMMC1_R>;
				cap-sd-highspeed;
				cap-mmc-highspeed;
				max-frequency = <50000000>;
				access-controllers = <&etzpc STM32MP1_ETZPC_SDMMC1_ID>;
				pinctrl-names = "default", "opendrain", "sleep";
				pinctrl-0 = <&sdmmc1_b4_pins_a &sdmmc1_clk_pins_a>;
				pinctrl-1 = <&sdmmc1_b4_od_pins_a &sdmmc1_clk_pins_a>;
				pinctrl-2 = <&sdmmc1_b4_sleep_pins_a>;
				broken-cd; // TODO: use this: cd-gpios = <&gpioi 7 (GPIO_ACTIVE_LOW)>;
				disable-wp;
				no-1-8-v;
				st,neg-edge;
				bus-width = <4>;
				vmmc-supply = <&vdd_sd>;
				vqmmc-supply = <&vdd_sd>;
				status = "okay";
			};

			sdmmc2: mmc@58007000 {
				compatible = "st,stm32-sdmmc2", "arm,pl18x", "arm,primecell";
				arm,primecell-periphid = <0x20253180>;
				reg = <0x58007000 0x1000>, <0x58008000 0x1000>;
				interrupts = <GIC_SPI 108 IRQ_TYPE_LEVEL_HIGH>;
				clocks = <&rcc SDMMC2_K>;
				clock-names = "apb_pclk";
				resets = <&rcc SDMMC2_R>;
				cap-sd-highspeed;
				cap-mmc-highspeed;
				max-frequency = <130000000>;
				access-controllers = <&etzpc STM32MP1_ETZPC_SDMMC2_ID>;
				status = "disabled";
			};

			eth1: eth1@5800a000 {
				compatible = "snps,dwmac-4.20a", "st,stm32mp13-dwmac";
				reg = <0x5800a000 0x2000>;
				reg-names = "stmmaceth";
				interrupts-extended = <&intc GIC_SPI 62 IRQ_TYPE_LEVEL_HIGH>,
						      <&exti 68 1>;
				interrupt-names = "macirq", "eth_wake_irq";
				clock-names = "stmmaceth",
					      "mac-clk-tx",
					      "mac-clk-rx",
					      "ethstp",
					      "eth-ck";
				clocks = <&rcc ETH1MAC>,
					 <&rcc ETH1TX>,
					 <&rcc ETH1RX>,
					 <&rcc ETH1STP>,
					 <&rcc ETH1CK_K>;
				st,syscon = <&syscfg 0x4 0xff0000>;
				snps,mixed-burst;
				snps,pbl = <2>;
				snps,axi-config = <&stmmac_axi_config_1>;
				snps,tso;
				access-controllers = <&etzpc STM32MP1_ETZPC_ETH1_ID>;
				status = "okay";
				pinctrl-0 = <&eth1_rmii_pins_a>;
				pinctrl-1 = <&eth1_rmii_sleep_pins_a>;
				pinctrl-names = "default", "sleep";
				phy-mode = "rmii";
				max-speed = <100>;
				phy-handle = <&phy0_eth1>;
				mac-address = [00 19 B3 12 12 34];
				snps,en-tx-lpi-clockgating;
				st,ext-phyclk;

				mdio1 {
					#address-cells = <1>;
					#size-cells = <0>;
					compatible = "snps,dwmac-mdio";

					phy0_eth1: ethernet-phy@0 {
						compatible = "ethernet-phy-id0007.c131";
						reset-gpios =  <&gpiog 11 GPIO_ACTIVE_LOW>;
						reg = <0>;
						wakeup-source;
					};
				};

				stmmac_axi_config_1: stmmac-axi-config {
					snps,wr_osr_lmt = <0x7>;
					snps,rd_osr_lmt = <0x7>;
					snps,blen = <0 0 0 0 16 8 4>;
				};
			};

			eth2: eth2@5800e000 {
				compatible = "snps,dwmac-4.20a", "st,stm32mp13-dwmac";
				reg = <0x5800e000 0x2000>;
				reg-names = "stmmaceth";
				interrupts-extended = <&intc GIC_SPI 97 IRQ_TYPE_LEVEL_HIGH>;
				interrupt-names = "macirq";
				clock-names = "stmmaceth",
					      "mac-clk-tx",
					      "mac-clk-rx",
					      "ethstp",
					      "eth-ck";
				clocks = <&rcc ETH2MAC>,
					 <&rcc ETH2TX>,
					 <&rcc ETH2RX>,
					 <&rcc ETH2STP>,
					 <&rcc ETH2CK_K>;
				st,syscon = <&syscfg 0x4 0xff000000>;
				snps,mixed-burst;
				snps,pbl = <2>;
				snps,axi-config = <&stmmac_axi_config_2>;
				snps,tso;
				access-controllers = <&etzpc STM32MP1_ETZPC_ETH2_ID>;
				status = "disabled";

				stmmac_axi_config_2: stmmac-axi-config {
					snps,wr_osr_lmt = <0x7>;
					snps,rd_osr_lmt = <0x7>;
					snps,blen = <0 0 0 0 16 8 4>;
				};
			};

			usbphyc: usbphyc@5a006000 {
				#address-cells = <1>;
				#size-cells = <0>;
				#clock-cells = <0>;
				compatible = "st,stm32mp1-usbphyc";
				reg = <0x5a006000 0x1000>;
				clocks = <&rcc USBPHY_K>;
				resets = <&rcc USBPHY_R>;
				//vdda1v1-supply = <&scmi_reg11>;
				//vdda1v8-supply = <&scmi_reg18>;
				access-controllers = <&etzpc STM32MP1_ETZPC_USBPHYCTRL_ID>;
				status = "okay";

				usbphyc_port0: usb-phy@0 {
					#phy-cells = <0>;
					reg = <0>;
					interrupts-extended = <&exti 42 IRQ_TYPE_LEVEL_HIGH>;
				};

				usbphyc_port1: usb-phy@1 {
					#phy-cells = <1>;
					reg = <1>;
					interrupts-extended = <&exti 43 IRQ_TYPE_LEVEL_HIGH>;
				};
			};
		};

		/*
		 * Break node order to solve dependency probe issue between
		 * pinctrl and exti.
		 */
		pinctrl: pinctrl@50002000 {
			#address-cells = <1>;
			#size-cells = <1>;
			compatible = "st,stm32mp135-pinctrl";
			ranges = <0 0x50002000 0x8400>;
			interrupt-parent = <&exti>;
			st,syscfg = <&exti 0x60 0xff>;
			pins-are-numbered;

			gpioa: gpio@50002000 {
				gpio-controller;
				#gpio-cells = <2>;
				interrupt-controller;
				#interrupt-cells = <2>;
				reg = <0x0 0x400>;
				clocks = <&rcc GPIOA>;
				st,bank-name = "GPIOA";
				ngpios = <16>;
				gpio-ranges = <&pinctrl 0 0 16>;
			};

			gpiob: gpio@50003000 {
				gpio-controller;
				#gpio-cells = <2>;
				interrupt-controller;
				#interrupt-cells = <2>;
				reg = <0x1000 0x400>;
				clocks = <&rcc GPIOB>;
				st,bank-name = "GPIOB";
				ngpios = <16>;
				gpio-ranges = <&pinctrl 0 16 16>;
			};

			gpioc: gpio@50004000 {
				gpio-controller;
				#gpio-cells = <2>;
				interrupt-controller;
				#interrupt-cells = <2>;
				reg = <0x2000 0x400>;
				clocks = <&rcc GPIOC>;
				st,bank-name = "GPIOC";
				ngpios = <16>;
				gpio-ranges = <&pinctrl 0 32 16>;
			};

			gpiod: gpio@50005000 {
				gpio-controller;
				#gpio-cells = <2>;
				interrupt-controller;
				#interrupt-cells = <2>;
				reg = <0x3000 0x400>;
				clocks = <&rcc GPIOD>;
				st,bank-name = "GPIOD";
				ngpios = <16>;
				gpio-ranges = <&pinctrl 0 48 16>;
			};

			gpioe: gpio@50006000 {
				gpio-controller;
				#gpio-cells = <2>;
				interrupt-controller;
				#interrupt-cells = <2>;
				reg = <0x4000 0x400>;
				clocks = <&rcc GPIOE>;
				st,bank-name = "GPIOE";
				ngpios = <16>;
				gpio-ranges = <&pinctrl 0 64 16>;
			};

			gpiof: gpio@50007000 {
				gpio-controller;
				#gpio-cells = <2>;
				interrupt-controller;
				#interrupt-cells = <2>;
				reg = <0x5000 0x400>;
				clocks = <&rcc GPIOF>;
				st,bank-name = "GPIOF";
				ngpios = <16>;
				gpio-ranges = <&pinctrl 0 80 16>;
			};

			gpiog: gpio@50008000 {
				gpio-controller;
				#gpio-cells = <2>;
				interrupt-controller;
				#interrupt-cells = <2>;
				reg = <0x6000 0x400>;
				clocks = <&rcc GPIOG>;
				st,bank-name = "GPIOG";
				ngpios = <16>;
				gpio-ranges = <&pinctrl 0 96 16>;
			};

			gpioh: gpio@50009000 {
				gpio-controller;
				#gpio-cells = <2>;
				interrupt-controller;
				#interrupt-cells = <2>;
				reg = <0x7000 0x400>;
				clocks = <&rcc GPIOH>;
				st,bank-name = "GPIOH";
				ngpios = <15>;
				gpio-ranges = <&pinctrl 0 112 15>;
			};

			gpioi: gpio@5000a000 {
				gpio-controller;
				#gpio-cells = <2>;
				interrupt-controller;
				#interrupt-cells = <2>;
				reg = <0x8000 0x400>;
				clocks = <&rcc GPIOI>;
				st,bank-name = "GPIOI";
				ngpios = <8>;
				gpio-ranges = <&pinctrl 0 128 8>;
			};

			adc1_usb_cc_pins_a: adc1-usb-cc-pins-0 {
				pins {
					pinmux = <STM32_PINMUX('F', 12, ANALOG)>, /* ADC1 in6 */
						 <STM32_PINMUX('A', 3, ANALOG)>; /* ADC1 in12 */
				};
			};

			dcmipp_pins_a: dcmi-0 {
				pins1 {
					pinmux = <STM32_PINMUX('H',  8,  AF13)>,/* DCMI_HSYNC */
						 <STM32_PINMUX('G',  9,  AF13)>,/* DCMI_VSYNC */
						 <STM32_PINMUX('B',  7,  AF14)>,/* DCMI_PIXCLK */
						 <STM32_PINMUX('A',  9,  AF13)>,/* DCMI_D0 */
						 <STM32_PINMUX('D',  0,  AF13)>,/* DCMI_D1 */
						 <STM32_PINMUX('G', 10,  AF13)>,/* DCMI_D2 */
						 <STM32_PINMUX('E',  4,  AF13)>,/* DCMI_D3 */
						 <STM32_PINMUX('D', 11,  AF14)>,/* DCMI_D4 */
						 <STM32_PINMUX('D',  3,  AF13)>,/* DCMI_D5 */
						 <STM32_PINMUX('B',  8,  AF13)>,/* DCMI_D6 */
						 <STM32_PINMUX('E', 14,  AF13)>;/* DCMI_D7 */
					bias-disable;
				};
			};

			dcmipp_sleep_pins_a: dcmi-sleep-0 {
				pins1 {
					pinmux = <STM32_PINMUX('H',  8,  ANALOG)>,/* DCMI_HSYNC */
						 <STM32_PINMUX('G',  9,  ANALOG)>,/* DCMI_VSYNC */
						 <STM32_PINMUX('B',  7,  ANALOG)>,/* DCMI_PIXCLK */
						 <STM32_PINMUX('A',  9,  ANALOG)>,/* DCMI_D0 */
						 <STM32_PINMUX('D',  0,  ANALOG)>,/* DCMI_D1 */
						 <STM32_PINMUX('G', 10,  ANALOG)>,/* DCMI_D2 */
						 <STM32_PINMUX('E',  4,  ANALOG)>,/* DCMI_D3 */
						 <STM32_PINMUX('D', 11,  ANALOG)>,/* DCMI_D4 */
						 <STM32_PINMUX('D',  3,  ANALOG)>,/* DCMI_D5 */
						 <STM32_PINMUX('B',  8,  ANALOG)>,/* DCMI_D6 */
						 <STM32_PINMUX('E', 14,  ANALOG)>;/* DCMI_D7 */
				};
			};

			dfsdm_clkout_pins_a: dfsdm-clkout-pins-0 {
				pins {
					pinmux = <STM32_PINMUX('C', 3, AF3)>; /* DFSDM_CKOUT */
					bias-disable;
					drive-push-pull;
					slew-rate = <0>;
				};
			};

			dfsdm_clkout_sleep_pins_a: dfsdm-clkout-sleep-pins-0 {
				pins {
					pinmux = <STM32_PINMUX('C', 3, ANALOG)>; /* DFSDM_CKOUT */
				};
			};

			dfsdm_datin1_pins_a: dfsdm-datin1-pins-0 {
				pins {
					pinmux = <STM32_PINMUX('B', 1, AF6)>; /* DFSDM_DATIN1 */
				};
			};

			dfsdm_datin1_sleep_pins_a: dfsdm-datin1-sleep-pins-0 {
				pins {
					pinmux = <STM32_PINMUX('B', 1, ANALOG)>; /* DFSDM_DATIN1 */
				};
			};

			dfsdm_datin3_pins_a: dfsdm-datin3-pins-0 {
				pins {
					pinmux = <STM32_PINMUX('F', 13, AF6)>; /* DFSDM_DATIN3 */
				};
			};

			dfsdm_datin3_sleep_pins_a: dfsdm-datin3-sleep-pins-0 {
				pins {
					pinmux = <STM32_PINMUX('F', 13, ANALOG)>; /* DFSDM_DATIN3 */
				};
			};

			eth1_rmii_pins_a: eth1-rmii-0 {
				pins1 {
					pinmux = <STM32_PINMUX('G', 13, AF11)>, /* ETH_RMII_TXD0 */
						 <STM32_PINMUX('G', 14, AF11)>, /* ETH_RMII_TXD1 */
						 <STM32_PINMUX('B', 11, AF11)>, /* ETH_RMII_TX_EN */
						 <STM32_PINMUX('A', 11, AF11)>, /* ETH_RMII_ETHCK */
						 <STM32_PINMUX('G', 3, AF11)>, /* ETH_MDIO */
						 <STM32_PINMUX('G', 2, AF11)>; /* ETH_MDC */
					bias-disable;
					drive-push-pull;
					slew-rate = <1>;
				};

				pins2 {
					pinmux = <STM32_PINMUX('C', 4, AF11)>, /* ETH_RMII_RXD0 */
						 <STM32_PINMUX('C', 5, AF11)>, /* ETH_RMII_RXD1 */
						 <STM32_PINMUX('A', 7, AF11)>; /* ETH_RMII_CRS_DV */
					bias-disable;
				};

			};

			eth1_rmii_sleep_pins_a: eth1-rmii-sleep-0 {
				pins1 {
					pinmux = <STM32_PINMUX('G', 13, ANALOG)>, /* ETH_RMII_TXD0 */
						 <STM32_PINMUX('G', 14, ANALOG)>, /* ETH_RMII_TXD1 */
						 <STM32_PINMUX('B', 11, ANALOG)>, /* ETH_RMII_TX_EN */
						 <STM32_PINMUX('A', 11, ANALOG)>, /* ETH_RMII_ETHCK */
						 <STM32_PINMUX('A', 2, ANALOG)>, /* ETH_MDIO */
						 <STM32_PINMUX('G', 2, ANALOG)>, /* ETH_MDC */
						 <STM32_PINMUX('C', 4, ANALOG)>, /* ETH_RMII_RXD0 */
						 <STM32_PINMUX('C', 5, ANALOG)>, /* ETH_RMII_RXD1 */
						 <STM32_PINMUX('C', 1, ANALOG)>; /* ETH_RMII_CRS_DV */
				};
			};

			eth2_rmii_pins_a: eth2-rmii-0 {
				pins1 {
					pinmux = <STM32_PINMUX('F', 7, AF11)>, /* ETH_RMII_TXD0 */
						 <STM32_PINMUX('G', 11, AF10)>, /* ETH_RMII_TXD1 */
						 <STM32_PINMUX('G', 8, AF13)>, /* ETH_RMII_ETHCK */
						 <STM32_PINMUX('F', 6, AF11)>, /* ETH_RMII_TX_EN */
						 <STM32_PINMUX('B', 2, AF11)>, /* ETH_MDIO */
						 <STM32_PINMUX('G', 5, AF10)>; /* ETH_MDC */
					bias-disable;
					drive-push-pull;
					slew-rate = <1>;
				};

				pins2 {
					pinmux = <STM32_PINMUX('F', 4, AF11)>, /* ETH_RMII_RXD0 */
						 <STM32_PINMUX('E', 2, AF10)>, /* ETH_RMII_RXD1 */
						 <STM32_PINMUX('A', 12, AF11)>; /* ETH_RMII_CRS_DV */
					bias-disable;
				};
			};

			eth2_rmii_sleep_pins_a: eth2-rmii-sleep-0 {
				pins1 {
					pinmux = <STM32_PINMUX('F', 7, ANALOG)>, /* ETH_RMII_TXD0 */
						 <STM32_PINMUX('G', 11, ANALOG)>, /* ETH_RMII_TXD1 */
						 <STM32_PINMUX('G', 8, ANALOG)>, /* ETH_RMII_ETHCK */
						 <STM32_PINMUX('F', 6, ANALOG)>, /* ETH_RMII_TX_EN */
						 <STM32_PINMUX('B', 2, ANALOG)>, /* ETH_MDIO */
						 <STM32_PINMUX('G', 5, ANALOG)>, /* ETH_MDC */
						 <STM32_PINMUX('F', 4, ANALOG)>, /* ETH_RMII_RXD0 */
						 <STM32_PINMUX('E', 2, ANALOG)>, /* ETH_RMII_RXD1 */
						 <STM32_PINMUX('A', 12, ANALOG)>; /* ETH_RMII_CRS_DV */
				};
			};

			goodix_pins_a: goodix-0 {
				pins {
					pinmux = <STM32_PINMUX('H', 12, GPIO)>;
					bias-pull-down;
				};
			};

			i2c1_pins_a: i2c1-0 {
				pins {
					pinmux = <STM32_PINMUX('D', 12, AF5)>, /* I2C1_SCL */
						 <STM32_PINMUX('E', 8, AF5)>; /* I2C1_SDA */
					bias-disable;
					drive-open-drain;
					slew-rate = <0>;
				};
			};

			i2c1_sleep_pins_a: i2c1-sleep-0 {
				pins {
					pinmux = <STM32_PINMUX('D', 12, ANALOG)>, /* I2C1_SCL */
						 <STM32_PINMUX('E', 8, ANALOG)>; /* I2C1_SDA */
				};
			};

			i2c4_pins_a: i2c4-0 {
				pins {
					pinmux = <STM32_PINMUX('E', 15, AF6)>, /* I2C4_SCL */
						 <STM32_PINMUX('B', 9, AF6)>; /* I2C4_SDA */
					bias-disable;
					drive-open-drain;
					slew-rate = <0>;
				};
			};

			i2c5_pins_a: i2c5-0 {
				pins {
					pinmux = <STM32_PINMUX('H', 13, AF4)>, /* I2C5_SCL */
						 <STM32_PINMUX('F', 3, AF4)>; /* I2C5_SDA */
					bias-disable;
					drive-open-drain;
					slew-rate = <0>;
				};
			};

			i2c5_sleep_pins_a: i2c5-sleep-0 {
				pins {
					pinmux = <STM32_PINMUX('H', 13, ANALOG)>, /* I2C5_SCL */
						 <STM32_PINMUX('F', 3, ANALOG)>; /* I2C5_SDA */
				};
			};

			ltdc_pins_a: ltdc-0 {
				pins {
					pinmux = <STM32_PINMUX('D',  9, AF13)>, /* LCD_CLK */
						 <STM32_PINMUX('E',  1, AF9)>,  /* LCD_HSYNC */
						 <STM32_PINMUX('E', 12, AF9)>,  /* LCD_VSYNC */
						 <STM32_PINMUX('G',  6, AF14)>, /* LCD_DE */
						 <STM32_PINMUX('B', 12, AF13)>, /* LCD_R3 */
						 <STM32_PINMUX('E',  3, AF13)>, /* LCD_R4 */
						 <STM32_PINMUX('F',  5, AF14)>, /* LCD_R5 */
						 <STM32_PINMUX('F',  0, AF13)>, /* LCD_R6 */
						 <STM32_PINMUX('F',  6, AF13)>, /* LCD_R7 */
						 <STM32_PINMUX('F',  7, AF14)>, /* LCD_G2 */
						 <STM32_PINMUX('E',  6, AF14)>, /* LCD_G3 */
						 <STM32_PINMUX('G',  5, AF11)>, /* LCD_G4 */
						 <STM32_PINMUX('G',  0, AF14)>, /* LCD_G5 */
						 <STM32_PINMUX('A', 12, AF14)>, /* LCD_G6 */
						 <STM32_PINMUX('A', 15, AF11)>, /* LCD_G7 */
						 <STM32_PINMUX('G', 15, AF14)>, /* LCD_B3 */
						 <STM32_PINMUX('B',  2, AF11)>, /* LCD_B4 */
						 <STM32_PINMUX('H',  9, AF9)>,  /* LCD_B5 */
						 <STM32_PINMUX('F',  4, AF13)>, /* LCD_B6 */
						 <STM32_PINMUX('B',  6, AF14)>; /* LCD_B7 */
					bias-disable;
					drive-push-pull;
					slew-rate = <0>;
				};
			};

			ltdc_sleep_pins_a: ltdc-sleep-0 {
				pins {
					pinmux = <STM32_PINMUX('D',  9, ANALOG)>, /* LCD_CLK */
						 <STM32_PINMUX('E',  1, ANALOG)>,  /* LCD_HSYNC */
						 <STM32_PINMUX('E', 12, ANALOG)>,  /* LCD_VSYNC */
						 <STM32_PINMUX('G',  6, ANALOG)>, /* LCD_DE */
						 <STM32_PINMUX('B', 12, ANALOG)>, /* LCD_R3 */
						 <STM32_PINMUX('E',  3, ANALOG)>, /* LCD_R4 */
						 <STM32_PINMUX('F',  5, ANALOG)>, /* LCD_R5 */
						 <STM32_PINMUX('F',  0, ANALOG)>, /* LCD_R6 */
						 <STM32_PINMUX('F',  6, ANALOG)>, /* LCD_R7 */
						 <STM32_PINMUX('F',  7, ANALOG)>, /* LCD_G2 */
						 <STM32_PINMUX('E',  6, ANALOG)>, /* LCD_G3 */
						 <STM32_PINMUX('G',  5, ANALOG)>, /* LCD_G4 */
						 <STM32_PINMUX('G',  0, ANALOG)>, /* LCD_G5 */
						 <STM32_PINMUX('A', 12, ANALOG)>, /* LCD_G6 */
						 <STM32_PINMUX('A', 15, ANALOG)>, /* LCD_G7 */
						 <STM32_PINMUX('G', 15, ANALOG)>, /* LCD_B3 */
						 <STM32_PINMUX('B',  2, ANALOG)>, /* LCD_B4 */
						 <STM32_PINMUX('H',  9, ANALOG)>,  /* LCD_B5 */
						 <STM32_PINMUX('F',  4, ANALOG)>, /* LCD_B6 */
						 <STM32_PINMUX('B',  6, ANALOG)>; /* LCD_B7 */
				};
			};

			mcp23017_pins_a: mcp23017-0 {
				pins {
					pinmux = <STM32_PINMUX('G', 12, GPIO)>;
					bias-pull-up;
				};
			};

			pwm1_pins: pwm1-0 {
				pins {
					pinmux = <STM32_PINMUX('B', 15, AF1)>; /* TIM1_CH3N */
					bias-pull-down;
					drive-push-pull;
					slew-rate = <0>;
				};
			};

			pwm3_sleep_pins_a: pwm3-sleep-0 {
				pins {
					pinmux = <STM32_PINMUX('B', 1, ANALOG)>; /* TIM3_CH4 */
				};
			};

			pwm4_pins_a: pwm4-0 {
				pins {
					pinmux = <STM32_PINMUX('D', 13, AF2)>; /* TIM4_CH2 */
					bias-pull-down;
					drive-push-pull;
					slew-rate = <0>;
				};
			};

			pwm4_sleep_pins_a: pwm4-sleep-0 {
				pins {
					pinmux = <STM32_PINMUX('D', 13, ANALOG)>; /* TIM4_CH2 */
				};
			};

			pwm8_pins_a: pwm8-0 {
				pins {
					pinmux = <STM32_PINMUX('E', 5, AF3)>; /* TIM8_CH3 */
					bias-pull-down;
					drive-push-pull;
					slew-rate = <0>;
				};
			};

			pwm8_sleep_pins_a: pwm8-sleep-0 {
				pins {
					pinmux = <STM32_PINMUX('E', 5, ANALOG)>; /* TIM8_CH3 */
				};
			};

			pwm14_pins_a: pwm14-0 {
				pins {
					pinmux = <STM32_PINMUX('F', 9, AF9)>; /* TIM14_CH1 */
					bias-pull-down;
					drive-push-pull;
					slew-rate = <0>;
				};
			};

			pwm14_sleep_pins_a: pwm14-sleep-0 {
				pins {
					pinmux = <STM32_PINMUX('F', 9, ANALOG)>; /* TIM14_CH1 */
				};
			};

			rtc_out2_rmp_pins_a: rtc-out2-rmp-pins-0 {
				pins {
					pinmux = <STM32_PINMUX('I', 1, ANALOG)>; /* RTC_OUT2_RMP */
				};
			};

			sai1_pins_a: sai1-0 {
				pins {
					pinmux = <STM32_PINMUX('A', 4, AF12)>, /* SAI1_SCK_A */
						 <STM32_PINMUX('A', 0, AF6)>, /* SAI1_SD_B */
						 <STM32_PINMUX('A', 5, AF6)>, /* SAI1_SD_A */
						 <STM32_PINMUX('F', 11, AF6)>; /* SAI1_FS_A */
					slew-rate = <0>;
					drive-push-pull;
					bias-disable;
				};
			};

			sai1_sleep_pins_a: sai1-sleep-0 {
				pins {
					pinmux = <STM32_PINMUX('A', 4, ANALOG)>, /* SAI1_SCK_A */
						 <STM32_PINMUX('A', 0, ANALOG)>, /* SAI1_SD_B */
						 <STM32_PINMUX('A', 5, ANALOG)>, /* SAI1_SD_A */
						 <STM32_PINMUX('F', 11, ANALOG)>; /* SAI1_FS_A */
				};
			};

			sdmmc1_b4_pins_a: sdmmc1-b4-0 {
				pins {
					pinmux = <STM32_PINMUX('C', 8, AF12)>, /* SDMMC1_D0 */
						 <STM32_PINMUX('C', 9, AF12)>, /* SDMMC1_D1 */
						 <STM32_PINMUX('C', 10, AF12)>, /* SDMMC1_D2 */
						 <STM32_PINMUX('C', 11, AF12)>, /* SDMMC1_D3 */
						 <STM32_PINMUX('D', 2, AF12)>; /* SDMMC1_CMD */
					slew-rate = <1>;
					drive-push-pull;
					bias-pull-up;
				};
			};

			sdmmc1_b4_od_pins_a: sdmmc1-b4-od-0 {
				pins1 {
					pinmux = <STM32_PINMUX('C', 8, AF12)>, /* SDMMC1_D0 */
						 <STM32_PINMUX('C', 9, AF12)>, /* SDMMC1_D1 */
						 <STM32_PINMUX('C', 10, AF12)>, /* SDMMC1_D2 */
						 <STM32_PINMUX('C', 11, AF12)>; /* SDMMC1_D3 */
					slew-rate = <1>;
					drive-push-pull;
					bias-pull-up;
				};
				pins2 {
					pinmux = <STM32_PINMUX('D', 2, AF12)>; /* SDMMC1_CMD */
					slew-rate = <1>;
					drive-open-drain;
					bias-disable;
				};
			};

			sdmmc1_b4_sleep_pins_a: sdmmc1-b4-sleep-0 {
				pins {
					pinmux = <STM32_PINMUX('C', 8, ANALOG)>, /* SDMMC1_D0 */
						 <STM32_PINMUX('C', 9, ANALOG)>, /* SDMMC1_D1 */
						 <STM32_PINMUX('C', 10, ANALOG)>, /* SDMMC1_D2 */
						 <STM32_PINMUX('C', 11, ANALOG)>, /* SDMMC1_D3 */
						 <STM32_PINMUX('C', 12, ANALOG)>, /* SDMMC1_CK */
						 <STM32_PINMUX('D', 2, ANALOG)>; /* SDMMC1_CMD */
				};
			};

			sdmmc1_clk_pins_a: sdmmc1-clk-0 {
				pins {
					pinmux = <STM32_PINMUX('C', 12, AF12)>; /* SDMMC1_CK */
					slew-rate = <1>;
					drive-push-pull;
					bias-pull-up;
				};
			};

			sdmmc2_b4_pins_a: sdmmc2-b4-0 {
				pins {
					pinmux = <STM32_PINMUX('B', 14, AF10)>, /* SDMMC2_D0 */
						 <STM32_PINMUX('B', 15, AF10)>, /* SDMMC2_D1 */
						 <STM32_PINMUX('B', 3, AF10)>, /* SDMMC2_D2 */
						 <STM32_PINMUX('B', 4, AF10)>, /* SDMMC2_D3 */
						 <STM32_PINMUX('G', 6, AF10)>; /* SDMMC2_CMD */
					slew-rate = <1>;
					drive-push-pull;
					bias-pull-up;
				};
			};

			sdmmc2_b4_od_pins_a: sdmmc2-b4-od-0 {
				pins1 {
					pinmux = <STM32_PINMUX('B', 14, AF10)>, /* SDMMC2_D0 */
						 <STM32_PINMUX('B', 15, AF10)>, /* SDMMC2_D1 */
						 <STM32_PINMUX('B', 3, AF10)>, /* SDMMC2_D2 */
						 <STM32_PINMUX('B', 4, AF10)>; /* SDMMC2_D3 */
					slew-rate = <1>;
					drive-push-pull;
					bias-pull-up;
				};
				pins2 {
					pinmux = <STM32_PINMUX('G', 6, AF10)>; /* SDMMC2_CMD */
					slew-rate = <1>;
					drive-open-drain;
					bias-pull-up;
				};
			};

			sdmmc2_b4_sleep_pins_a: sdmmc2-b4-sleep-0 {
				pins {
					pinmux = <STM32_PINMUX('B', 14, ANALOG)>, /* SDMMC2_D0 */
						 <STM32_PINMUX('B', 15, ANALOG)>, /* SDMMC2_D1 */
						 <STM32_PINMUX('B', 3, ANALOG)>, /* SDMMC2_D2 */
						 <STM32_PINMUX('B', 4, ANALOG)>, /* SDMMC2_D3 */
						 <STM32_PINMUX('E', 3, ANALOG)>, /* SDMMC2_CK */
						 <STM32_PINMUX('G', 6, ANALOG)>; /* SDMMC2_CMD */
				};
			};

			sdmmc2_clk_pins_a: sdmmc2-clk-0 {
				pins {
					pinmux = <STM32_PINMUX('E', 3, AF10)>; /* SDMMC2_CK */
					slew-rate = <1>;
					drive-push-pull;
					bias-pull-up;
				};
			};

			fmc_nand_pins: fmc-nand-0 {
				pins1 {
					pinmux = <STM32_PINMUX('D', 14, AF12)>,  /* FMC_D0  */
						 <STM32_PINMUX('D', 15, AF12)>,  /* FMC_D1  */
						 <STM32_PINMUX('D',  0, AF12)>,  /* FMC_D2  */
						 <STM32_PINMUX('D',  1, AF12)>,  /* FMC_D3  */
						 <STM32_PINMUX('E',  7, AF12)>,  /* FMC_D4  */
						 <STM32_PINMUX('E',  8, AF12)>,  /* FMC_D5  */
						 <STM32_PINMUX('E',  9, AF12)>,  /* FMC_D6  */
						 <STM32_PINMUX('E', 10, AF12)>,  /* FMC_D7  */
						 <STM32_PINMUX('D',  4, AF12)>,  /* FMC_NOE */
						 <STM32_PINMUX('D',  5, AF12)>,  /* FMC_NWE */
						 <STM32_PINMUX('D', 11, AF12)>,  /* FMC_CLE */
						 <STM32_PINMUX('D', 12, AF12)>,  /* FMC_ALE */
						 <STM32_PINMUX('G',  9, AF12)>;  /* FMC_NCE */
					bias-disable;
					drive-push-pull;
					slew-rate = <3>;
				};
				pins2 {
					pinmux = <STM32_PINMUX('A', 9, AF10)>;   /* FMC_NWAIT */
					bias-disable;                              /* external 10k pull-up */
				};
			};

			spi5_pins_a: spi5-0 {
				pins1 {
					pinmux = <STM32_PINMUX('H', 7, AF6)>, /* SPI5_SCK */
						 <STM32_PINMUX('H', 3, AF5)>; /* SPI5_MOSI */
					bias-disable;
					drive-push-pull;
					slew-rate = <1>;
				};

				pins2 {
					pinmux = <STM32_PINMUX('A', 8, AF5)>; /* SPI5_MISO */
					bias-disable;
				};
			};

			spi5_sleep_pins_a: spi5-sleep-0 {
				pins {
					pinmux = <STM32_PINMUX('H', 7, ANALOG)>, /* SPI5_SCK */
						 <STM32_PINMUX('A', 8, ANALOG)>, /* SPI5_MISO */
						 <STM32_PINMUX('H', 3, ANALOG)>; /* SPI5_MOSI */
				};
			};

			stm32g0_intn_pins_a: stm32g0-intn-0 {
				pins {
					pinmux = <STM32_PINMUX('I', 2, GPIO)>;
					bias-pull-up;
				};
			};

			uart4_pins_a: uart4-0 {
				pins1 {
					pinmux = <STM32_PINMUX('D', 6, AF8)>; /* UART4_TX */
					bias-disable;
					drive-push-pull;
					slew-rate = <0>;
				};
				pins2 {
					pinmux = <STM32_PINMUX('D', 8, AF8)>; /* UART4_RX */
					bias-pull-up;
				};
			};

			uart4_idle_pins_a: uart4-idle-0 {
				pins1 {
					pinmux = <STM32_PINMUX('D', 6, ANALOG)>; /* UART4_TX */
				};
				pins2 {
					pinmux = <STM32_PINMUX('D', 8, AF8)>; /* UART4_RX */
					bias-pull-up;
				};
			};

			uart4_sleep_pins_a: uart4-sleep-0 {
				pins {
					pinmux = <STM32_PINMUX('D', 6, ANALOG)>, /* UART4_TX */
						 <STM32_PINMUX('D', 8, ANALOG)>; /* UART4_RX */
				};
			};

			uart8_pins_a: uart8-0 {
				pins1 {
					pinmux = <STM32_PINMUX('E', 1, AF8)>; /* UART8_TX */
					bias-disable;
					drive-push-pull;
					slew-rate = <0>;
				};
				pins2 {
					pinmux = <STM32_PINMUX('F', 9, AF8)>; /* UART8_RX */
					bias-pull-up;
				};
			};

			uart8_idle_pins_a: uart8-idle-0 {
				pins1 {
					pinmux = <STM32_PINMUX('E', 1, ANALOG)>; /* UART8_TX */
				};
				pins2 {
					pinmux = <STM32_PINMUX('F', 9, AF8)>; /* UART8_RX */
					bias-pull-up;
				};
			};

			uart8_sleep_pins_a: uart8-sleep-0 {
				pins {
					pinmux = <STM32_PINMUX('E', 1, ANALOG)>, /* UART8_TX */
						 <STM32_PINMUX('F', 9, ANALOG)>; /* UART8_RX */
				};
			};

			usart1_pins_a: usart1-0 {
				pins1 {
					pinmux = <STM32_PINMUX('C', 0, AF7)>, /* USART1_TX */
						 <STM32_PINMUX('C', 2, AF7)>; /* USART1_RTS */
					bias-disable;
					drive-push-pull;
					slew-rate = <0>;
				};
				pins2 {
					pinmux = <STM32_PINMUX('B', 0, AF4)>, /* USART1_RX */
						 <STM32_PINMUX('A', 7, AF7)>; /* USART1_CTS_NSS */
					bias-pull-up;
				};
			};

			usart1_idle_pins_a: usart1-idle-0 {
				pins1 {
					pinmux = <STM32_PINMUX('C', 0, ANALOG)>, /* USART1_TX */
						 <STM32_PINMUX('A', 7, ANALOG)>; /* USART1_CTS_NSS */
				};
				pins2 {
					pinmux = <STM32_PINMUX('C', 2, AF7)>; /* USART1_RTS */
					bias-disable;
					drive-push-pull;
					slew-rate = <0>;
				};
				pins3 {
					pinmux = <STM32_PINMUX('B', 0, AF4)>; /* USART1_RX */
					bias-pull-up;
				};
			};

			usart1_sleep_pins_a: usart1-sleep-0 {
				pins {
					pinmux = <STM32_PINMUX('C', 0, ANALOG)>, /* USART1_TX */
						 <STM32_PINMUX('C', 2, ANALOG)>, /* USART1_RTS */
						 <STM32_PINMUX('A', 7, ANALOG)>, /* USART1_CTS_NSS */
						 <STM32_PINMUX('B', 0, ANALOG)>; /* USART1_RX */
				};
			};

			usart2_pins_a: usart2-0 {
				pins1 {
					pinmux = <STM32_PINMUX('H', 12, AF1)>, /* USART2_TX */
						 <STM32_PINMUX('D', 4, AF3)>; /* USART2_RTS */
					bias-disable;
					drive-push-pull;
					slew-rate = <0>;
				};
				pins2 {
					pinmux = <STM32_PINMUX('D', 15, AF1)>, /* USART2_RX */
						 <STM32_PINMUX('E', 11, AF2)>; /* USART2_CTS_NSS */
					bias-disable;
				};
			};

			usart2_idle_pins_a: usart2-idle-0 {
				pins1 {
					pinmux = <STM32_PINMUX('H', 12, ANALOG)>, /* USART2_TX */
						 <STM32_PINMUX('E', 11, ANALOG)>; /* USART2_CTS_NSS */
				};
				pins2 {
					pinmux = <STM32_PINMUX('D', 4, AF3)>; /* USART2_RTS */
					bias-disable;
					drive-push-pull;
					slew-rate = <0>;
				};
				pins3 {
					pinmux = <STM32_PINMUX('D', 15, AF1)>; /* USART2_RX */
					bias-disable;
				};
			};

			usart2_sleep_pins_a: usart2-sleep-0 {
				pins {
					pinmux = <STM32_PINMUX('H', 12, ANALOG)>, /* USART2_TX */
						 <STM32_PINMUX('D', 4, ANALOG)>, /* USART2_RTS */
						 <STM32_PINMUX('D', 15, ANALOG)>, /* USART2_RX */
						 <STM32_PINMUX('E', 11, ANALOG)>; /* USART2_CTS_NSS */
				};
			};
		};
	};
};
